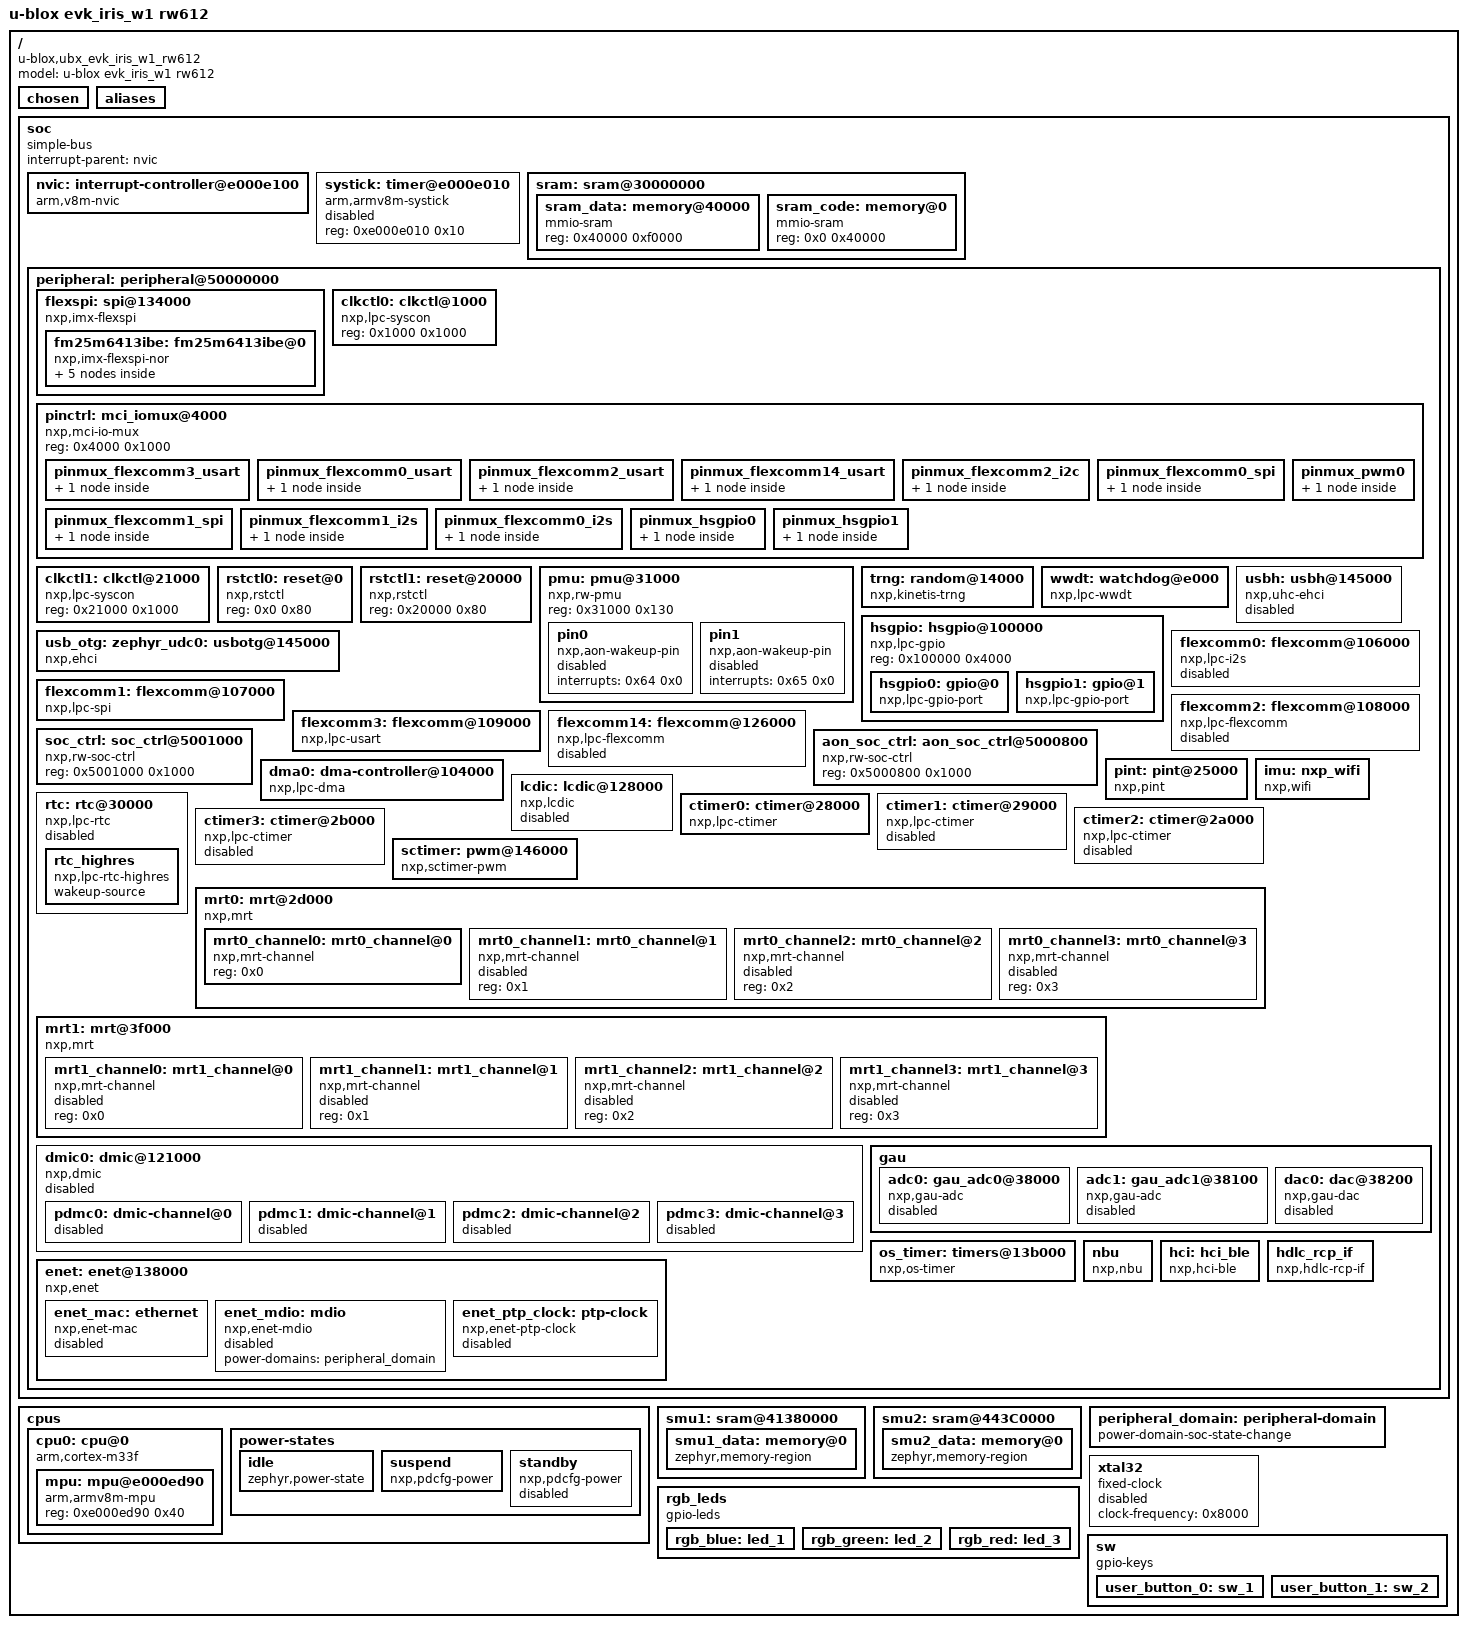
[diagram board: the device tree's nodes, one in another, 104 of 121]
/dts-v1/;

/* node '/' defined in zephyr/dts/common/skeleton.dtsi:9 */
/ {
	#address-cells = < 0x1 >;                    /* in zephyr/dts/common/skeleton.dtsi:10 */
	#size-cells = < 0x1 >;                       /* in zephyr/dts/common/skeleton.dtsi:11 */
	model = "u-blox evk_iris_w1 rw612";          /* in zephyr/boards/u-blox/ubx_evk_iris_w1/ubx_evk_iris_w1_common.dtsi:11 */
	compatible = "u-blox,ubx_evk_iris_w1_rw612"; /* in zephyr/boards/u-blox/ubx_evk_iris_w1/ubx_evk_iris_w1_common.dtsi:12 */

	/* node '/chosen' defined in zephyr/dts/common/skeleton.dtsi:13 */
	chosen {
		zephyr,entropy = &trng;                   /* in zephyr/dts/arm/nxp/nxp_rw6xx_common.dtsi:18 */
		zephyr,nbu = &nbu;                        /* in zephyr/dts/arm/nxp/nxp_rw6xx_common.dtsi:19 */
		zephyr,bt-hci = &hci;                     /* in zephyr/dts/arm/nxp/nxp_rw6xx_common.dtsi:20 */
		zephyr,hdlc-rcp-if = &hdlc_rcp_if;        /* in zephyr/dts/arm/nxp/nxp_rw6xx_common.dtsi:21 */
		zephyr,sram = &sram_data;                 /* in zephyr/boards/u-blox/ubx_evk_iris_w1/ubx_evk_iris_w1_common.dtsi:28 */
		zephyr,flash = &fm25m6413ibe;             /* in zephyr/boards/u-blox/ubx_evk_iris_w1/ubx_evk_iris_w1_common.dtsi:29 */
		zephyr,console = &flexcomm3;              /* in zephyr/boards/u-blox/ubx_evk_iris_w1/ubx_evk_iris_w1_common.dtsi:30 */
		zephyr,shell-uart = &flexcomm3;           /* in zephyr/boards/u-blox/ubx_evk_iris_w1/ubx_evk_iris_w1_common.dtsi:31 */
		zephyr,flash-controller = &fm25m6413ibe;  /* in zephyr/boards/u-blox/ubx_evk_iris_w1/ubx_evk_iris_w1_common.dtsi:32 */
		zephyr,code-partition = &slot0_partition; /* in zephyr/boards/u-blox/ubx_evk_iris_w1/ubx_evk_iris_w1_common.dtsi:33 */
		zephyr,uart-mcumgr = &flexcomm3;          /* in zephyr/boards/u-blox/ubx_evk_iris_w1/ubx_evk_iris_w1_common.dtsi:34 */
	};

	/* node '/aliases' defined in zephyr/dts/common/skeleton.dtsi:15 */
	aliases {
		led0 = &rgb_red;      /* in zephyr/boards/u-blox/ubx_evk_iris_w1/ubx_evk_iris_w1_common.dtsi:15 */
		led1 = &rgb_green;    /* in zephyr/boards/u-blox/ubx_evk_iris_w1/ubx_evk_iris_w1_common.dtsi:16 */
		led2 = &rgb_blue;     /* in zephyr/boards/u-blox/ubx_evk_iris_w1/ubx_evk_iris_w1_common.dtsi:17 */
		sw0 = &user_button_0; /* in zephyr/boards/u-blox/ubx_evk_iris_w1/ubx_evk_iris_w1_common.dtsi:18 */
		sw1 = &user_button_1; /* in zephyr/boards/u-blox/ubx_evk_iris_w1/ubx_evk_iris_w1_common.dtsi:19 */
		watchdog0 = &wwdt;    /* in zephyr/boards/u-blox/ubx_evk_iris_w1/ubx_evk_iris_w1_common.dtsi:20 */
		usart-0 = &flexcomm3; /* in zephyr/boards/u-blox/ubx_evk_iris_w1/ubx_evk_iris_w1_common.dtsi:21 */
		i2s-0 = &flexcomm0;   /* in zephyr/boards/u-blox/ubx_evk_iris_w1/ubx_evk_iris_w1_common.dtsi:22 */
		i2c-2 = &flexcomm2;   /* in zephyr/boards/u-blox/ubx_evk_iris_w1/ubx_evk_iris_w1_common.dtsi:23 */
		pwm-0 = &sctimer;     /* in zephyr/boards/u-blox/ubx_evk_iris_w1/ubx_evk_iris_w1_common.dtsi:24 */
	};

	/* node '/soc' defined in zephyr/dts/arm/armv8-m.dtsi:6 */
	soc {
		#address-cells = < 0x1 >;     /* in zephyr/dts/arm/armv8-m.dtsi:7 */
		#size-cells = < 0x1 >;        /* in zephyr/dts/arm/armv8-m.dtsi:8 */
		compatible = "simple-bus";    /* in zephyr/dts/arm/armv8-m.dtsi:9 */
		interrupt-parent = < &nvic >; /* in zephyr/dts/arm/armv8-m.dtsi:10 */
		ranges;                       /* in zephyr/dts/arm/armv8-m.dtsi:11 */

		/* node '/soc/interrupt-controller@e000e100' defined in zephyr/dts/arm/armv8-m.dtsi:13 */
		nvic: interrupt-controller@e000e100 {
			#address-cells = < 0x1 >;            /* in zephyr/dts/arm/armv8-m.dtsi:14 */
			compatible = "arm,v8m-nvic";         /* in zephyr/dts/arm/armv8-m.dtsi:15 */
			reg = < 0xe000e100 0xc00 >;          /* in zephyr/dts/arm/armv8-m.dtsi:16 */
			interrupt-controller;                /* in zephyr/dts/arm/armv8-m.dtsi:17 */
			#interrupt-cells = < 0x2 >;          /* in zephyr/dts/arm/armv8-m.dtsi:18 */
			arm,num-irq-priority-bits = < 0x3 >; /* in zephyr/dts/arm/nxp/nxp_rw6xx_common.dtsi:677 */
			phandle = < 0x1 >;                   /* in zephyr/dts/arm/armv8-m.dtsi:10 */
		};

		/* node '/soc/timer@e000e010' defined in zephyr/dts/arm/armv8-m.dtsi:21 */
		systick: timer@e000e010 {
			compatible = "arm,armv8m-systick"; /* in zephyr/dts/arm/armv8-m.dtsi:22 */
			reg = < 0xe000e010 0x10 >;         /* in zephyr/dts/arm/armv8-m.dtsi:23 */
			status = "disabled";               /* in zephyr/boards/u-blox/ubx_evk_iris_w1/ubx_evk_iris_w1_common.dtsi:181 */
		};

		/* node '/soc/sram@30000000' defined in zephyr/dts/arm/nxp/nxp_rw6xx.dtsi:13 */
		sram: sram@30000000 {
			ranges = < 0x20000000 0x30000000 0x130000 0x0 0x10000000 0x130000 >; /* in zephyr/dts/arm/nxp/nxp_rw6xx.dtsi:14 */
			#address-cells = < 0x1 >;                                            /* in zephyr/dts/arm/nxp/nxp_rw6xx_common.dtsi:103 */
			#size-cells = < 0x1 >;                                               /* in zephyr/dts/arm/nxp/nxp_rw6xx_common.dtsi:104 */

			/* node '/soc/sram@30000000/memory@40000' defined in zephyr/dts/arm/nxp/nxp_rw6xx_common.dtsi:111 */
			sram_data: memory@40000 {
				compatible = "mmio-sram";  /* in zephyr/dts/arm/nxp/nxp_rw6xx_common.dtsi:112 */
				reg = < 0x40000 0xf0000 >; /* in zephyr/dts/arm/nxp/nxp_rw6xx_common.dtsi:113 */
			};

			/* node '/soc/sram@30000000/memory@0' defined in zephyr/dts/arm/nxp/nxp_rw6xx_common.dtsi:116 */
			sram_code: memory@0 {
				compatible = "mmio-sram"; /* in zephyr/dts/arm/nxp/nxp_rw6xx_common.dtsi:117 */
				reg = < 0x0 0x40000 >;    /* in zephyr/dts/arm/nxp/nxp_rw6xx_common.dtsi:118 */
			};
		};

		/* node '/soc/peripheral@50000000' defined in zephyr/dts/arm/nxp/nxp_rw6xx.dtsi:18 */
		peripheral: peripheral@50000000 {
			ranges = < 0x0 0x50000000 0x10000000 >; /* in zephyr/dts/arm/nxp/nxp_rw6xx.dtsi:19 */
			#address-cells = < 0x1 >;               /* in zephyr/dts/arm/nxp/nxp_rw6xx_common.dtsi:147 */
			#size-cells = < 0x1 >;                  /* in zephyr/dts/arm/nxp/nxp_rw6xx_common.dtsi:148 */

			/* node '/soc/peripheral@50000000/spi@134000' defined in zephyr/dts/arm/nxp/nxp_rw6xx_common.dtsi:150 */
			flexspi: spi@134000 {
				reg = < 0x134000 0x1000 >,
				      < 0x18000000 0x8000000 >; /* in zephyr/dts/arm/nxp/nxp_rw6xx_common.dtsi:151 */
				compatible = "nxp,imx-flexspi"; /* in zephyr/dts/arm/nxp/nxp_rw6xx_common.dtsi:668 */
				interrupts = < 0x2a 0x0 >;      /* in zephyr/dts/arm/nxp/nxp_rw6xx_common.dtsi:670 */
				#address-cells = < 0x1 >;       /* in zephyr/dts/arm/nxp/nxp_rw6xx_common.dtsi:671 */
				#size-cells = < 0x0 >;          /* in zephyr/dts/arm/nxp/nxp_rw6xx_common.dtsi:672 */
				clocks = < &clkctl1 0xa00 >;    /* in zephyr/dts/arm/nxp/nxp_rw6xx_common.dtsi:673 */
				status = "okay";                /* in zephyr/boards/u-blox/ubx_evk_iris_w1/ubx_evk_iris_w1_common.dtsi:101 */
				ahb-bufferable;                 /* in zephyr/boards/u-blox/ubx_evk_iris_w1/ubx_evk_iris_w1_common.dtsi:102 */
				ahb-prefetch;                   /* in zephyr/boards/u-blox/ubx_evk_iris_w1/ubx_evk_iris_w1_common.dtsi:103 */
				ahb-cacheable;                  /* in zephyr/boards/u-blox/ubx_evk_iris_w1/ubx_evk_iris_w1_common.dtsi:104 */
				ahb-read-addr-opt;              /* in zephyr/boards/u-blox/ubx_evk_iris_w1/ubx_evk_iris_w1_common.dtsi:105 */
				ahb-boundary = "1024";          /* in zephyr/boards/u-blox/ubx_evk_iris_w1/ubx_evk_iris_w1_common.dtsi:106 */
				rx-clock-source = < 0x1 >;      /* in zephyr/boards/u-blox/ubx_evk_iris_w1/ubx_evk_iris_w1_common.dtsi:107 */
				rx-clock-source-b = < 0x1 >;    /* in zephyr/boards/u-blox/ubx_evk_iris_w1/ubx_evk_iris_w1_common.dtsi:108 */

				/* node '/soc/peripheral@50000000/spi@134000/fm25m6413ibe@0' defined in zephyr/boards/u-blox/ubx_evk_iris_w1/ubx_evk_iris_w1_common.dtsi:111 */
				fm25m6413ibe: fm25m6413ibe@0 {
					compatible = "nxp,imx-flexspi-nor"; /* in zephyr/boards/u-blox/ubx_evk_iris_w1/ubx_evk_iris_w1_common.dtsi:112 */
					reg = < 0x0 >;                      /* in zephyr/boards/u-blox/ubx_evk_iris_w1/ubx_evk_iris_w1_common.dtsi:113 */
					size = < 0x4000000 >;               /* in zephyr/boards/u-blox/ubx_evk_iris_w1/ubx_evk_iris_w1_common.dtsi:114 */
					status = "okay";                    /* in zephyr/boards/u-blox/ubx_evk_iris_w1/ubx_evk_iris_w1_common.dtsi:115 */
					erase-block-size = < 0x1000 >;      /* in zephyr/boards/u-blox/ubx_evk_iris_w1/ubx_evk_iris_w1_common.dtsi:116 */
					write-block-size = < 0x1 >;         /* in zephyr/boards/u-blox/ubx_evk_iris_w1/ubx_evk_iris_w1_common.dtsi:117 */
					spi-max-frequency = < 0x7ed6b40 >;  /* in zephyr/boards/u-blox/ubx_evk_iris_w1/ubx_evk_iris_w1_common.dtsi:118 */

					/* node '/soc/peripheral@50000000/spi@134000/fm25m6413ibe@0/partitions' defined in zephyr/boards/u-blox/ubx_evk_iris_w1/ubx_evk_iris_w1_common.dtsi:120 */
					partitions {
						compatible = "fixed-partitions"; /* in zephyr/boards/u-blox/ubx_evk_iris_w1/ubx_evk_iris_w1_common.dtsi:121 */
						#address-cells = < 0x1 >;        /* in zephyr/boards/u-blox/ubx_evk_iris_w1/ubx_evk_iris_w1_common.dtsi:122 */
						#size-cells = < 0x1 >;           /* in zephyr/boards/u-blox/ubx_evk_iris_w1/ubx_evk_iris_w1_common.dtsi:123 */

						/* node '/soc/peripheral@50000000/spi@134000/fm25m6413ibe@0/partitions/partition@0' defined in zephyr/boards/u-blox/ubx_evk_iris_w1/ubx_evk_iris_w1_common.dtsi:129 */
						boot_partition: partition@0 {
							label = "mcuboot";     /* in zephyr/boards/u-blox/ubx_evk_iris_w1/ubx_evk_iris_w1_common.dtsi:130 */
							reg = < 0x0 0x20000 >; /* in zephyr/boards/u-blox/ubx_evk_iris_w1/ubx_evk_iris_w1_common.dtsi:131 */
						};

						/* node '/soc/peripheral@50000000/spi@134000/fm25m6413ibe@0/partitions/partition@20000' defined in zephyr/boards/u-blox/ubx_evk_iris_w1/ubx_evk_iris_w1_common.dtsi:134 */
						slot0_partition: partition@20000 {
							label = "image-0";          /* in zephyr/boards/u-blox/ubx_evk_iris_w1/ubx_evk_iris_w1_common.dtsi:135 */
							reg = < 0x20000 0x300000 >; /* in zephyr/boards/u-blox/ubx_evk_iris_w1/ubx_evk_iris_w1_common.dtsi:136 */
						};

						/* node '/soc/peripheral@50000000/spi@134000/fm25m6413ibe@0/partitions/partition@320000' defined in zephyr/boards/u-blox/ubx_evk_iris_w1/ubx_evk_iris_w1_common.dtsi:139 */
						slot1_partition: partition@320000 {
							label = "image-1";           /* in zephyr/boards/u-blox/ubx_evk_iris_w1/ubx_evk_iris_w1_common.dtsi:140 */
							reg = < 0x320000 0x300000 >; /* in zephyr/boards/u-blox/ubx_evk_iris_w1/ubx_evk_iris_w1_common.dtsi:141 */
						};

						/* node '/soc/peripheral@50000000/spi@134000/fm25m6413ibe@0/partitions/partition@620000' defined in zephyr/boards/u-blox/ubx_evk_iris_w1/ubx_evk_iris_w1_common.dtsi:144 */
						storage_partition: partition@620000 {
							label = "storage";           /* in zephyr/boards/u-blox/ubx_evk_iris_w1/ubx_evk_iris_w1_common.dtsi:145 */
							reg = < 0x620000 0x1e0000 >; /* in zephyr/boards/u-blox/ubx_evk_iris_w1/ubx_evk_iris_w1_common.dtsi:146 */
						};
					};
				};
			};

			/* node '/soc/peripheral@50000000/clkctl@1000' defined in zephyr/dts/arm/nxp/nxp_rw6xx_common.dtsi:154 */
			clkctl0: clkctl@1000 {
				compatible = "nxp,lpc-syscon"; /* in zephyr/dts/arm/nxp/nxp_rw6xx_common.dtsi:156 */
				reg = < 0x1000 0x1000 >;       /* in zephyr/dts/arm/nxp/nxp_rw6xx_common.dtsi:157 */
				#clock-cells = < 0x1 >;        /* in zephyr/dts/arm/nxp/nxp_rw6xx_common.dtsi:158 */
			};

			/* node '/soc/peripheral@50000000/mci_iomux@4000' defined in zephyr/dts/arm/nxp/nxp_rw6xx_common.dtsi:161 */
			pinctrl: mci_iomux@4000 {
				compatible = "nxp,mci-io-mux"; /* in zephyr/dts/arm/nxp/nxp_rw6xx_common.dtsi:162 */
				reg = < 0x4000 0x1000 >;       /* in zephyr/dts/arm/nxp/nxp_rw6xx_common.dtsi:163 */
				status = "okay";               /* in zephyr/dts/arm/nxp/nxp_rw6xx_common.dtsi:164 */

				/* node '/soc/peripheral@50000000/mci_iomux@4000/pinmux_flexcomm3_usart' defined in zephyr/boards/u-blox/ubx_evk_iris_w1/ubx_evk_iris_w1_rw612-pinctrl.dtsi:11 */
				pinmux_flexcomm3_usart: pinmux_flexcomm3_usart {
					phandle = < 0xc >; /* in zephyr/boards/u-blox/ubx_evk_iris_w1/ubx_evk_iris_w1_common.dtsi:77 */

					/* node '/soc/peripheral@50000000/mci_iomux@4000/pinmux_flexcomm3_usart/group0' defined in zephyr/boards/u-blox/ubx_evk_iris_w1/ubx_evk_iris_w1_rw612-pinctrl.dtsi:12 */
					group0 {
						pinmux = < 0x49818 0x4981a >; /* in zephyr/boards/u-blox/ubx_evk_iris_w1/ubx_evk_iris_w1_rw612-pinctrl.dtsi:13 */
						slew-rate = "normal";         /* in zephyr/boards/u-blox/ubx_evk_iris_w1/ubx_evk_iris_w1_rw612-pinctrl.dtsi:14 */
					};
				};

				/* node '/soc/peripheral@50000000/mci_iomux@4000/pinmux_flexcomm0_usart' defined in zephyr/boards/u-blox/ubx_evk_iris_w1/ubx_evk_iris_w1_rw612-pinctrl.dtsi:19 */
				pinmux_flexcomm0_usart: pinmux_flexcomm0_usart {

					/* node '/soc/peripheral@50000000/mci_iomux@4000/pinmux_flexcomm0_usart/group0' defined in zephyr/boards/u-blox/ubx_evk_iris_w1/ubx_evk_iris_w1_rw612-pinctrl.dtsi:20 */
					group0 {
						pinmux = < 0x48002 0x48003 >; /* in zephyr/boards/u-blox/ubx_evk_iris_w1/ubx_evk_iris_w1_rw612-pinctrl.dtsi:21 */
						slew-rate = "normal";         /* in zephyr/boards/u-blox/ubx_evk_iris_w1/ubx_evk_iris_w1_rw612-pinctrl.dtsi:22 */
					};
				};

				/* node '/soc/peripheral@50000000/mci_iomux@4000/pinmux_flexcomm2_usart' defined in zephyr/boards/u-blox/ubx_evk_iris_w1/ubx_evk_iris_w1_rw612-pinctrl.dtsi:26 */
				pinmux_flexcomm2_usart: pinmux_flexcomm2_usart {

					/* node '/soc/peripheral@50000000/mci_iomux@4000/pinmux_flexcomm2_usart/group0' defined in zephyr/boards/u-blox/ubx_evk_iris_w1/ubx_evk_iris_w1_rw612-pinctrl.dtsi:27 */
					group0 {
						pinmux = < 0x4900d 0x4900e >; /* in zephyr/boards/u-blox/ubx_evk_iris_w1/ubx_evk_iris_w1_rw612-pinctrl.dtsi:28 */
						slew-rate = "normal";         /* in zephyr/boards/u-blox/ubx_evk_iris_w1/ubx_evk_iris_w1_rw612-pinctrl.dtsi:29 */
					};
				};

				/* node '/soc/peripheral@50000000/mci_iomux@4000/pinmux_flexcomm14_usart' defined in zephyr/boards/u-blox/ubx_evk_iris_w1/ubx_evk_iris_w1_rw612-pinctrl.dtsi:33 */
				pinmux_flexcomm14_usart: pinmux_flexcomm14_usart {

					/* node '/soc/peripheral@50000000/mci_iomux@4000/pinmux_flexcomm14_usart/group0' defined in zephyr/boards/u-blox/ubx_evk_iris_w1/ubx_evk_iris_w1_rw612-pinctrl.dtsi:34 */
					group0 {
						pinmux = < 0x4b038 0x4b039 >; /* in zephyr/boards/u-blox/ubx_evk_iris_w1/ubx_evk_iris_w1_rw612-pinctrl.dtsi:35 */
						slew-rate = "normal";         /* in zephyr/boards/u-blox/ubx_evk_iris_w1/ubx_evk_iris_w1_rw612-pinctrl.dtsi:36 */
					};
				};

				/* node '/soc/peripheral@50000000/mci_iomux@4000/pinmux_flexcomm2_i2c' defined in zephyr/boards/u-blox/ubx_evk_iris_w1/ubx_evk_iris_w1_rw612-pinctrl.dtsi:41 */
				pinmux_flexcomm2_i2c: pinmux_flexcomm2_i2c {

					/* node '/soc/peripheral@50000000/mci_iomux@4000/pinmux_flexcomm2_i2c/group0' defined in zephyr/boards/u-blox/ubx_evk_iris_w1/ubx_evk_iris_w1_rw612-pinctrl.dtsi:42 */
					group0 {
						pinmux = < 0x21010 0x21011 >; /* in zephyr/boards/u-blox/ubx_evk_iris_w1/ubx_evk_iris_w1_rw612-pinctrl.dtsi:43 */
						slew-rate = "normal";         /* in zephyr/boards/u-blox/ubx_evk_iris_w1/ubx_evk_iris_w1_rw612-pinctrl.dtsi:44 */
						bias-pull-up;                 /* in zephyr/boards/u-blox/ubx_evk_iris_w1/ubx_evk_iris_w1_rw612-pinctrl.dtsi:45 */
					};
				};

				/* node '/soc/peripheral@50000000/mci_iomux@4000/pinmux_flexcomm0_spi' defined in zephyr/boards/u-blox/ubx_evk_iris_w1/ubx_evk_iris_w1_rw612-pinctrl.dtsi:50 */
				pinmux_flexcomm0_spi: pinmux_flexcomm0_spi {

					/* node '/soc/peripheral@50000000/mci_iomux@4000/pinmux_flexcomm0_spi/group0' defined in zephyr/boards/u-blox/ubx_evk_iris_w1/ubx_evk_iris_w1_rw612-pinctrl.dtsi:51 */
					group0 {
						pinmux = < 0x18000 0x18002 0x18003 0x18004 >; /* in zephyr/boards/u-blox/ubx_evk_iris_w1/ubx_evk_iris_w1_rw612-pinctrl.dtsi:52 */
						slew-rate = "ultra";                          /* in zephyr/boards/u-blox/ubx_evk_iris_w1/ubx_evk_iris_w1_rw612-pinctrl.dtsi:53 */
					};
				};

				/* node '/soc/peripheral@50000000/mci_iomux@4000/pinmux_flexcomm1_spi' defined in zephyr/boards/u-blox/ubx_evk_iris_w1/ubx_evk_iris_w1_rw612-pinctrl.dtsi:58 */
				pinmux_flexcomm1_spi: pinmux_flexcomm1_spi {
					phandle = < 0xb >; /* in zephyr/boards/u-blox/ubx_evk_iris_w1/ubx_evk_iris_w1_common.dtsi:211 */

					/* node '/soc/peripheral@50000000/mci_iomux@4000/pinmux_flexcomm1_spi/group0' defined in zephyr/boards/u-blox/ubx_evk_iris_w1/ubx_evk_iris_w1_rw612-pinctrl.dtsi:59 */
					group0 {
						pinmux = < 0x18806 0x18807 0x18808 0x18809 >; /* in zephyr/boards/u-blox/ubx_evk_iris_w1/ubx_evk_iris_w1_rw612-pinctrl.dtsi:60 */
						slew-rate = "ultra";                          /* in zephyr/boards/u-blox/ubx_evk_iris_w1/ubx_evk_iris_w1_rw612-pinctrl.dtsi:61 */
					};
				};

				/* node '/soc/peripheral@50000000/mci_iomux@4000/pinmux_flexcomm1_i2s' defined in zephyr/boards/u-blox/ubx_evk_iris_w1/ubx_evk_iris_w1_rw612-pinctrl.dtsi:66 */
				pinmux_flexcomm1_i2s: pinmux_flexcomm1_i2s {

					/* node '/soc/peripheral@50000000/mci_iomux@4000/pinmux_flexcomm1_i2s/group0' defined in zephyr/boards/u-blox/ubx_evk_iris_w1/ubx_evk_iris_w1_rw612-pinctrl.dtsi:67 */
					group0 {
						pinmux = < 0x10807 0x10808 0x10809 >; /* in zephyr/boards/u-blox/ubx_evk_iris_w1/ubx_evk_iris_w1_rw612-pinctrl.dtsi:68 */
						slew-rate = "normal";                 /* in zephyr/boards/u-blox/ubx_evk_iris_w1/ubx_evk_iris_w1_rw612-pinctrl.dtsi:69 */
					};
				};

				/* node '/soc/peripheral@50000000/mci_iomux@4000/pinmux_flexcomm0_i2s' defined in zephyr/boards/u-blox/ubx_evk_iris_w1/ubx_evk_iris_w1_rw612-pinctrl.dtsi:73 */
				pinmux_flexcomm0_i2s: pinmux_flexcomm0_i2s {
					phandle = < 0xa >; /* in zephyr/boards/u-blox/ubx_evk_iris_w1/ubx_evk_iris_w1_common.dtsi:84 */

					/* node '/soc/peripheral@50000000/mci_iomux@4000/pinmux_flexcomm0_i2s/group0' defined in zephyr/boards/u-blox/ubx_evk_iris_w1/ubx_evk_iris_w1_rw612-pinctrl.dtsi:74 */
					group0 {
						pinmux = < 0x10002 0x10003 0x10004 >; /* in zephyr/boards/u-blox/ubx_evk_iris_w1/ubx_evk_iris_w1_rw612-pinctrl.dtsi:75 */
						slew-rate = "normal";                 /* in zephyr/boards/u-blox/ubx_evk_iris_w1/ubx_evk_iris_w1_rw612-pinctrl.dtsi:76 */
					};
				};

				/* node '/soc/peripheral@50000000/mci_iomux@4000/pinmux_pwm0' defined in zephyr/boards/u-blox/ubx_evk_iris_w1/ubx_evk_iris_w1_rw612-pinctrl.dtsi:80 */
				pinmux_pwm0: pinmux_pwm0 {
					phandle = < 0xd >; /* in zephyr/boards/u-blox/ubx_evk_iris_w1/ubx_evk_iris_w1_common.dtsi:186 */

					/* node '/soc/peripheral@50000000/mci_iomux@4000/pinmux_pwm0/group0' defined in zephyr/boards/u-blox/ubx_evk_iris_w1/ubx_evk_iris_w1_rw612-pinctrl.dtsi:81 */
					group0 {
						pinmux = < 0x283 >;   /* in zephyr/boards/u-blox/ubx_evk_iris_w1/ubx_evk_iris_w1_rw612-pinctrl.dtsi:82 */
						slew-rate = "normal"; /* in zephyr/boards/u-blox/ubx_evk_iris_w1/ubx_evk_iris_w1_rw612-pinctrl.dtsi:83 */
					};
				};

				/* node '/soc/peripheral@50000000/mci_iomux@4000/pinmux_hsgpio0' defined in zephyr/boards/u-blox/ubx_evk_iris_w1/ubx_evk_iris_w1_rw612-pinctrl.dtsi:87 */
				pinmux_hsgpio0: pinmux_hsgpio0 {
					phandle = < 0x4 >; /* in zephyr/boards/u-blox/ubx_evk_iris_w1/ubx_evk_iris_w1_common.dtsi:90 */

					/* node '/soc/peripheral@50000000/mci_iomux@4000/pinmux_hsgpio0/group0' defined in zephyr/boards/u-blox/ubx_evk_iris_w1/ubx_evk_iris_w1_rw612-pinctrl.dtsi:88 */
					group0 {
						pinmux = < 0x30b 0x30c 0x312 0x315 >; /* in zephyr/boards/u-blox/ubx_evk_iris_w1/ubx_evk_iris_w1_rw612-pinctrl.dtsi:89 */
						slew-rate = "normal";                 /* in zephyr/boards/u-blox/ubx_evk_iris_w1/ubx_evk_iris_w1_rw612-pinctrl.dtsi:93 */
					};
				};

				/* node '/soc/peripheral@50000000/mci_iomux@4000/pinmux_hsgpio1' defined in zephyr/boards/u-blox/ubx_evk_iris_w1/ubx_evk_iris_w1_rw612-pinctrl.dtsi:97 */
				pinmux_hsgpio1: pinmux_hsgpio1 {
					phandle = < 0x5 >; /* in zephyr/boards/u-blox/ubx_evk_iris_w1/ubx_evk_iris_w1_common.dtsi:96 */

					/* node '/soc/peripheral@50000000/mci_iomux@4000/pinmux_hsgpio1/group0' defined in zephyr/boards/u-blox/ubx_evk_iris_w1/ubx_evk_iris_w1_rw612-pinctrl.dtsi:98 */
					group0 {
						pinmux = < 0x32c 0x337 >; /* in zephyr/boards/u-blox/ubx_evk_iris_w1/ubx_evk_iris_w1_rw612-pinctrl.dtsi:99 */
						slew-rate = "normal";     /* in zephyr/boards/u-blox/ubx_evk_iris_w1/ubx_evk_iris_w1_rw612-pinctrl.dtsi:101 */
					};
				};
			};

			/* node '/soc/peripheral@50000000/clkctl@21000' defined in zephyr/dts/arm/nxp/nxp_rw6xx_common.dtsi:167 */
			clkctl1: clkctl@21000 {
				compatible = "nxp,lpc-syscon"; /* in zephyr/dts/arm/nxp/nxp_rw6xx_common.dtsi:169 */
				reg = < 0x21000 0x1000 >;      /* in zephyr/dts/arm/nxp/nxp_rw6xx_common.dtsi:170 */
				#clock-cells = < 0x1 >;        /* in zephyr/dts/arm/nxp/nxp_rw6xx_common.dtsi:171 */
				phandle = < 0x2 >;             /* in zephyr/dts/arm/nxp/nxp_rw6xx_common.dtsi:673 */
			};

			/* node '/soc/peripheral@50000000/reset@0' defined in zephyr/dts/arm/nxp/nxp_rw6xx_common.dtsi:174 */
			rstctl0: reset@0 {
				compatible = "nxp,rstctl"; /* in zephyr/dts/arm/nxp/nxp_rw6xx_common.dtsi:175 */
				reg = < 0x0 0x80 >;        /* in zephyr/dts/arm/nxp/nxp_rw6xx_common.dtsi:176 */
				#reset-cells = < 0x1 >;    /* in zephyr/dts/arm/nxp/nxp_rw6xx_common.dtsi:177 */
				phandle = < 0xe >;         /* in zephyr/dts/arm/nxp/nxp_rw6xx_common.dtsi:511 */
			};

			/* node '/soc/peripheral@50000000/reset@20000' defined in zephyr/dts/arm/nxp/nxp_rw6xx_common.dtsi:180 */
			rstctl1: reset@20000 {
				compatible = "nxp,rstctl"; /* in zephyr/dts/arm/nxp/nxp_rw6xx_common.dtsi:181 */
				reg = < 0x20000 0x80 >;    /* in zephyr/dts/arm/nxp/nxp_rw6xx_common.dtsi:182 */
				#reset-cells = < 0x1 >;    /* in zephyr/dts/arm/nxp/nxp_rw6xx_common.dtsi:183 */
				phandle = < 0x6 >;         /* in zephyr/dts/arm/nxp/nxp_rw6xx_common.dtsi:270 */
			};

			/* node '/soc/peripheral@50000000/pmu@31000' defined in zephyr/dts/arm/nxp/nxp_rw6xx_common.dtsi:186 */
			pmu: pmu@31000 {
				reg = < 0x31000 0x130 >;   /* in zephyr/dts/arm/nxp/nxp_rw6xx_common.dtsi:187 */
				compatible = "nxp,rw-pmu"; /* in zephyr/dts/arm/nxp/nxp_rw6xx_common.dtsi:188 */

				/* node '/soc/peripheral@50000000/pmu@31000/pin0' defined in zephyr/dts/arm/nxp/nxp_rw6xx_common.dtsi:190 */
				pin0: pin0 {
					compatible = "nxp,aon-wakeup-pin"; /* in zephyr/dts/arm/nxp/nxp_rw6xx_common.dtsi:191 */
					interrupts = < 0x64 0x0 >;         /* in zephyr/dts/arm/nxp/nxp_rw6xx_common.dtsi:192 */
					status = "disabled";               /* in zephyr/dts/arm/nxp/nxp_rw6xx_common.dtsi:193 */
				};

				/* node '/soc/peripheral@50000000/pmu@31000/pin1' defined in zephyr/dts/arm/nxp/nxp_rw6xx_common.dtsi:196 */
				pin1: pin1 {
					compatible = "nxp,aon-wakeup-pin"; /* in zephyr/dts/arm/nxp/nxp_rw6xx_common.dtsi:197 */
					interrupts = < 0x65 0x0 >;         /* in zephyr/dts/arm/nxp/nxp_rw6xx_common.dtsi:198 */
					status = "disabled";               /* in zephyr/dts/arm/nxp/nxp_rw6xx_common.dtsi:199 */
				};
			};

			/* node '/soc/peripheral@50000000/random@14000' defined in zephyr/dts/arm/nxp/nxp_rw6xx_common.dtsi:203 */
			trng: random@14000 {
				compatible = "nxp,kinetis-trng";        /* in zephyr/dts/arm/nxp/nxp_rw6xx_common.dtsi:204 */
				reg = < 0x14000 0x1000 >;               /* in zephyr/dts/arm/nxp/nxp_rw6xx_common.dtsi:205 */
				status = "okay";                        /* in zephyr/dts/arm/nxp/nxp_rw6xx_common.dtsi:206 */
				interrupts = < 0x7b 0x0 >;              /* in zephyr/dts/arm/nxp/nxp_rw6xx_common.dtsi:207 */
				power-domains = < &peripheral_domain >; /* in zephyr/dts/arm/nxp/nxp_rw6xx_common.dtsi:208 */
			};

			/* node '/soc/peripheral@50000000/watchdog@e000' defined in zephyr/dts/arm/nxp/nxp_rw6xx_common.dtsi:211 */
			wwdt: watchdog@e000 {
				compatible = "nxp,lpc-wwdt";            /* in zephyr/dts/arm/nxp/nxp_rw6xx_common.dtsi:212 */
				reg = < 0xe000 0x1000 >;                /* in zephyr/dts/arm/nxp/nxp_rw6xx_common.dtsi:213 */
				interrupts = < 0x0 0x0 >;               /* in zephyr/dts/arm/nxp/nxp_rw6xx_common.dtsi:214 */
				power-domains = < &peripheral_domain >; /* in zephyr/dts/arm/nxp/nxp_rw6xx_common.dtsi:216 */
				clk-divider = < 0x1 >;                  /* in zephyr/dts/arm/nxp/nxp_rw6xx_common.dtsi:217 */
				status = "okay";                        /* in zephyr/boards/u-blox/ubx_evk_iris_w1/ubx_evk_iris_w1_common.dtsi:158 */
			};

			/* node '/soc/peripheral@50000000/hsgpio@100000' defined in zephyr/dts/arm/nxp/nxp_rw6xx_common.dtsi:220 */
			hsgpio: hsgpio@100000 {
				compatible = "nxp,lpc-gpio"; /* in zephyr/dts/arm/nxp/nxp_rw6xx_common.dtsi:221 */
				reg = < 0x100000 0x4000 >;   /* in zephyr/dts/arm/nxp/nxp_rw6xx_common.dtsi:222 */
				#address-cells = < 0x1 >;    /* in zephyr/dts/arm/nxp/nxp_rw6xx_common.dtsi:223 */
				#size-cells = < 0x0 >;       /* in zephyr/dts/arm/nxp/nxp_rw6xx_common.dtsi:224 */

				/* node '/soc/peripheral@50000000/hsgpio@100000/gpio@0' defined in zephyr/dts/arm/nxp/nxp_rw6xx_common.dtsi:226 */
				hsgpio0: gpio@0 {
					compatible = "nxp,lpc-gpio-port";       /* in zephyr/dts/arm/nxp/nxp_rw6xx_common.dtsi:227 */
					gpio-controller;                        /* in zephyr/dts/arm/nxp/nxp_rw6xx_common.dtsi:228 */
					#gpio-cells = < 0x2 >;                  /* in zephyr/dts/arm/nxp/nxp_rw6xx_common.dtsi:229 */
					reg = < 0x0 >;                          /* in zephyr/dts/arm/nxp/nxp_rw6xx_common.dtsi:230 */
					int-source = "pint";                    /* in zephyr/dts/arm/nxp/nxp_rw6xx_common.dtsi:231 */
					power-domains = < &peripheral_domain >; /* in zephyr/dts/arm/nxp/nxp_rw6xx_common.dtsi:232 */
					status = "okay";                        /* in zephyr/boards/u-blox/ubx_evk_iris_w1/ubx_evk_iris_w1_common.dtsi:89 */
					pinctrl-0 = < &pinmux_hsgpio0 >;        /* in zephyr/boards/u-blox/ubx_evk_iris_w1/ubx_evk_iris_w1_common.dtsi:90 */
					pinctrl-names = "default";              /* in zephyr/boards/u-blox/ubx_evk_iris_w1/ubx_evk_iris_w1_common.dtsi:91 */
				};

				/* node '/soc/peripheral@50000000/hsgpio@100000/gpio@1' defined in zephyr/dts/arm/nxp/nxp_rw6xx_common.dtsi:235 */
				hsgpio1: gpio@1 {
					compatible = "nxp,lpc-gpio-port";       /* in zephyr/dts/arm/nxp/nxp_rw6xx_common.dtsi:236 */
					gpio-controller;                        /* in zephyr/dts/arm/nxp/nxp_rw6xx_common.dtsi:237 */
					#gpio-cells = < 0x2 >;                  /* in zephyr/dts/arm/nxp/nxp_rw6xx_common.dtsi:238 */
					reg = < 0x1 >;                          /* in zephyr/dts/arm/nxp/nxp_rw6xx_common.dtsi:239 */
					int-source = "pint";                    /* in zephyr/dts/arm/nxp/nxp_rw6xx_common.dtsi:240 */
					power-domains = < &peripheral_domain >; /* in zephyr/dts/arm/nxp/nxp_rw6xx_common.dtsi:241 */
					status = "okay";                        /* in zephyr/boards/u-blox/ubx_evk_iris_w1/ubx_evk_iris_w1_common.dtsi:95 */
					pinctrl-0 = < &pinmux_hsgpio1 >;        /* in zephyr/boards/u-blox/ubx_evk_iris_w1/ubx_evk_iris_w1_common.dtsi:96 */
					pinctrl-names = "default";              /* in zephyr/boards/u-blox/ubx_evk_iris_w1/ubx_evk_iris_w1_common.dtsi:97 */
					phandle = < 0x13 >;                     /* in zephyr/boards/u-blox/ubx_evk_iris_w1/ubx_evk_iris_w1_common.dtsi:41 */
				};
			};

			/* node '/soc/peripheral@50000000/usbotg@145000' defined in zephyr/dts/arm/nxp/nxp_rw6xx_common.dtsi:245 */
			usb_otg: zephyr_udc0: usbotg@145000 {
				compatible = "nxp,ehci";                /* in zephyr/dts/arm/nxp/nxp_rw6xx_common.dtsi:246 */
				reg = < 0x145000 0x200 >;               /* in zephyr/dts/arm/nxp/nxp_rw6xx_common.dtsi:247 */
				interrupts = < 0x32 0x1 >;              /* in zephyr/dts/arm/nxp/nxp_rw6xx_common.dtsi:248 */
				interrupt-names = "usb_otg";            /* in zephyr/dts/arm/nxp/nxp_rw6xx_common.dtsi:249 */
				num-bidir-endpoints = < 0x8 >;          /* in zephyr/dts/arm/nxp/nxp_rw6xx_common.dtsi:250 */
				power-domains = < &peripheral_domain >; /* in zephyr/dts/arm/nxp/nxp_rw6xx_common.dtsi:251 */
				status = "okay";                        /* in zephyr/boards/u-blox/ubx_evk_iris_w1/ubx_evk_iris_w1_common.dtsi:206 */
			};

			/* node '/soc/peripheral@50000000/usbh@145000' defined in zephyr/dts/arm/nxp/nxp_rw6xx_common.dtsi:255 */
			usbh: usbh@145000 {
				compatible = "nxp,uhc-ehci";            /* in zephyr/dts/arm/nxp/nxp_rw6xx_common.dtsi:256 */
				reg = < 0x145000 0x200 >;               /* in zephyr/dts/arm/nxp/nxp_rw6xx_common.dtsi:257 */
				interrupts = < 0x32 0x1 >;              /* in zephyr/dts/arm/nxp/nxp_rw6xx_common.dtsi:258 */
				interrupt-names = "usb_otg";            /* in zephyr/dts/arm/nxp/nxp_rw6xx_common.dtsi:259 */
				power-domains = < &peripheral_domain >; /* in zephyr/dts/arm/nxp/nxp_rw6xx_common.dtsi:260 */
				status = "disabled";                    /* in zephyr/dts/arm/nxp/nxp_rw6xx_common.dtsi:261 */
			};

			/* node '/soc/peripheral@50000000/flexcomm@106000' defined in zephyr/dts/arm/nxp/nxp_rw6xx_common.dtsi:264 */
			flexcomm0: flexcomm@106000 {
				reg = < 0x106000 0x1000 >;                             /* in zephyr/dts/arm/nxp/nxp_rw6xx_common.dtsi:266 */
				interrupts = < 0xe 0x0 >;                              /* in zephyr/dts/arm/nxp/nxp_rw6xx_common.dtsi:267 */
				clocks = < &clkctl1 0x100 &clkctl1 0x180 >;            /* in zephyr/dts/arm/nxp/nxp_rw6xx_common.dtsi:268 */
				clock-names = "default",
				              "sleep";                                 /* in zephyr/dts/arm/nxp/nxp_rw6xx_common.dtsi:269 */
				resets = < &rstctl1 0x8 >;                             /* in zephyr/dts/arm/nxp/nxp_rw6xx_common.dtsi:270 */
				dmas = < &dma0 0x0 >,
				       < &dma0 0x1 >;                                  /* in zephyr/dts/arm/nxp/nxp_rw6xx_common.dtsi:271 */
				dma-names = "rx",
				            "tx";                                      /* in zephyr/dts/arm/nxp/nxp_rw6xx_common.dtsi:272 */
				zephyr,disabling-power-states = < &suspend &standby >; /* in zephyr/dts/arm/nxp/nxp_rw6xx_common.dtsi:273 */
				low-power-states = < &suspend >;                       /* in zephyr/dts/arm/nxp/nxp_rw6xx_common.dtsi:274 */
				power-domains = < &peripheral_domain >;                /* in zephyr/dts/arm/nxp/nxp_rw6xx_common.dtsi:275 */
				compatible = "nxp,lpc-i2s";                            /* in zephyr/boards/u-blox/ubx_evk_iris_w1/ubx_evk_iris_w1_common.dtsi:82 */
				status = "disabled";                                   /* in zephyr/boards/u-blox/ubx_evk_iris_w1/ubx_evk_iris_w1_common.dtsi:83 */
				pinctrl-0 = < &pinmux_flexcomm0_i2s >;                 /* in zephyr/boards/u-blox/ubx_evk_iris_w1/ubx_evk_iris_w1_common.dtsi:84 */
				pinctrl-names = "default";                             /* in zephyr/boards/u-blox/ubx_evk_iris_w1/ubx_evk_iris_w1_common.dtsi:85 */
			};

			/* node '/soc/peripheral@50000000/flexcomm@107000' defined in zephyr/dts/arm/nxp/nxp_rw6xx_common.dtsi:279 */
			flexcomm1: flexcomm@107000 {
				reg = < 0x107000 0x1000 >;                             /* in zephyr/dts/arm/nxp/nxp_rw6xx_common.dtsi:281 */
				interrupts = < 0xf 0x0 >;                              /* in zephyr/dts/arm/nxp/nxp_rw6xx_common.dtsi:282 */
				clocks = < &clkctl1 0x101 &clkctl1 0x181 >;            /* in zephyr/dts/arm/nxp/nxp_rw6xx_common.dtsi:283 */
				clock-names = "default",
				              "sleep";                                 /* in zephyr/dts/arm/nxp/nxp_rw6xx_common.dtsi:284 */
				resets = < &rstctl1 0x9 >;                             /* in zephyr/dts/arm/nxp/nxp_rw6xx_common.dtsi:285 */
				dmas = < &dma0 0x2 >,
				       < &dma0 0x3 >;                                  /* in zephyr/dts/arm/nxp/nxp_rw6xx_common.dtsi:286 */
				dma-names = "rx",
				            "tx";                                      /* in zephyr/dts/arm/nxp/nxp_rw6xx_common.dtsi:287 */
				zephyr,disabling-power-states = < &suspend &standby >; /* in zephyr/dts/arm/nxp/nxp_rw6xx_common.dtsi:288 */
				low-power-states = < &suspend >;                       /* in zephyr/dts/arm/nxp/nxp_rw6xx_common.dtsi:289 */
				power-domains = < &peripheral_domain >;                /* in zephyr/dts/arm/nxp/nxp_rw6xx_common.dtsi:290 */
				compatible = "nxp,lpc-spi";                            /* in zephyr/boards/u-blox/ubx_evk_iris_w1/ubx_evk_iris_w1_common.dtsi:210 */
				pinctrl-0 = < &pinmux_flexcomm1_spi >;                 /* in zephyr/boards/u-blox/ubx_evk_iris_w1/ubx_evk_iris_w1_common.dtsi:211 */
				pinctrl-names = "default";                             /* in zephyr/boards/u-blox/ubx_evk_iris_w1/ubx_evk_iris_w1_common.dtsi:212 */
				status = "okay";                                       /* in zephyr/boards/u-blox/ubx_evk_iris_w1/ubx_evk_iris_w1_common.dtsi:213 */
				#address-cells = < 0x1 >;                              /* in zephyr/boards/u-blox/ubx_evk_iris_w1/ubx_evk_iris_w1_common.dtsi:214 */
				#size-cells = < 0x0 >;                                 /* in zephyr/boards/u-blox/ubx_evk_iris_w1/ubx_evk_iris_w1_common.dtsi:215 */
			};

			/* node '/soc/peripheral@50000000/flexcomm@108000' defined in zephyr/dts/arm/nxp/nxp_rw6xx_common.dtsi:294 */
			flexcomm2: flexcomm@108000 {
				compatible = "nxp,lpc-flexcomm";                       /* in zephyr/dts/arm/nxp/nxp_rw6xx_common.dtsi:295 */
				reg = < 0x108000 0x1000 >;                             /* in zephyr/dts/arm/nxp/nxp_rw6xx_common.dtsi:296 */
				interrupts = < 0x10 0x0 >;                             /* in zephyr/dts/arm/nxp/nxp_rw6xx_common.dtsi:297 */
				clocks = < &clkctl1 0x102 &clkctl1 0x182 >;            /* in zephyr/dts/arm/nxp/nxp_rw6xx_common.dtsi:298 */
				clock-names = "default",
				              "sleep";                                 /* in zephyr/dts/arm/nxp/nxp_rw6xx_common.dtsi:299 */
				resets = < &rstctl1 0xa >;                             /* in zephyr/dts/arm/nxp/nxp_rw6xx_common.dtsi:300 */
				dmas = < &dma0 0x4 >,
				       < &dma0 0x5 >;                                  /* in zephyr/dts/arm/nxp/nxp_rw6xx_common.dtsi:301 */
				dma-names = "rx",
				            "tx";                                      /* in zephyr/dts/arm/nxp/nxp_rw6xx_common.dtsi:302 */
				zephyr,disabling-power-states = < &suspend &standby >; /* in zephyr/dts/arm/nxp/nxp_rw6xx_common.dtsi:303 */
				low-power-states = < &suspend >;                       /* in zephyr/dts/arm/nxp/nxp_rw6xx_common.dtsi:304 */
				power-domains = < &peripheral_domain >;                /* in zephyr/dts/arm/nxp/nxp_rw6xx_common.dtsi:305 */
				status = "disabled";                                   /* in zephyr/dts/arm/nxp/nxp_rw6xx_common.dtsi:306 */
			};

			/* node '/soc/peripheral@50000000/flexcomm@109000' defined in zephyr/dts/arm/nxp/nxp_rw6xx_common.dtsi:309 */
			flexcomm3: flexcomm@109000 {
				reg = < 0x109000 0x1000 >;                             /* in zephyr/dts/arm/nxp/nxp_rw6xx_common.dtsi:311 */
				interrupts = < 0x11 0x0 >;                             /* in zephyr/dts/arm/nxp/nxp_rw6xx_common.dtsi:312 */
				clocks = < &clkctl1 0x103 &clkctl1 0x183 >;            /* in zephyr/dts/arm/nxp/nxp_rw6xx_common.dtsi:313 */
				clock-names = "default",
				              "sleep";                                 /* in zephyr/dts/arm/nxp/nxp_rw6xx_common.dtsi:314 */
				resets = < &rstctl1 0xb >;                             /* in zephyr/dts/arm/nxp/nxp_rw6xx_common.dtsi:315 */
				dmas = < &dma0 0x6 >,
				       < &dma0 0x7 >;                                  /* in zephyr/dts/arm/nxp/nxp_rw6xx_common.dtsi:316 */
				dma-names = "rx",
				            "tx";                                      /* in zephyr/dts/arm/nxp/nxp_rw6xx_common.dtsi:317 */
				zephyr,disabling-power-states = < &suspend &standby >; /* in zephyr/dts/arm/nxp/nxp_rw6xx_common.dtsi:318 */
				low-power-states = < &suspend >;                       /* in zephyr/dts/arm/nxp/nxp_rw6xx_common.dtsi:319 */
				power-domains = < &peripheral_domain >;                /* in zephyr/dts/arm/nxp/nxp_rw6xx_common.dtsi:320 */
				compatible = "nxp,lpc-usart";                          /* in zephyr/boards/u-blox/ubx_evk_iris_w1/ubx_evk_iris_w1_common.dtsi:74 */
				status = "okay";                                       /* in zephyr/boards/u-blox/ubx_evk_iris_w1/ubx_evk_iris_w1_common.dtsi:75 */
				current-speed = < 0x1c200 >;                           /* in zephyr/boards/u-blox/ubx_evk_iris_w1/ubx_evk_iris_w1_common.dtsi:76 */
				pinctrl-0 = < &pinmux_flexcomm3_usart >;               /* in zephyr/boards/u-blox/ubx_evk_iris_w1/ubx_evk_iris_w1_common.dtsi:77 */
				pinctrl-names = "default";                             /* in zephyr/boards/u-blox/ubx_evk_iris_w1/ubx_evk_iris_w1_common.dtsi:78 */
			};

			/* node '/soc/peripheral@50000000/flexcomm@126000' defined in zephyr/dts/arm/nxp/nxp_rw6xx_common.dtsi:324 */
			flexcomm14: flexcomm@126000 {
				compatible = "nxp,lpc-flexcomm";                       /* in zephyr/dts/arm/nxp/nxp_rw6xx_common.dtsi:325 */
				reg = < 0x126000 0x2000 >;                             /* in zephyr/dts/arm/nxp/nxp_rw6xx_common.dtsi:326 */
				interrupts = < 0x14 0x0 >;                             /* in zephyr/dts/arm/nxp/nxp_rw6xx_common.dtsi:327 */
				clocks = < &clkctl1 0x10e >;                           /* in zephyr/dts/arm/nxp/nxp_rw6xx_common.dtsi:328 */
				resets = < &rstctl1 0x16 >;                            /* in zephyr/dts/arm/nxp/nxp_rw6xx_common.dtsi:329 */
				dmas = < &dma0 0x1a >,
				       < &dma0 0x1b >;                                 /* in zephyr/dts/arm/nxp/nxp_rw6xx_common.dtsi:330 */
				dma-names = "rx",
				            "tx";                                      /* in zephyr/dts/arm/nxp/nxp_rw6xx_common.dtsi:331 */
				zephyr,disabling-power-states = < &suspend &standby >; /* in zephyr/dts/arm/nxp/nxp_rw6xx_common.dtsi:332 */
				power-domains = < &peripheral_domain >;                /* in zephyr/dts/arm/nxp/nxp_rw6xx_common.dtsi:333 */
				status = "disabled";                                   /* in zephyr/dts/arm/nxp/nxp_rw6xx_common.dtsi:334 */
			};

			/* node '/soc/peripheral@50000000/aon_soc_ctrl@5000800' defined in zephyr/dts/arm/nxp/nxp_rw6xx_common.dtsi:337 */
			aon_soc_ctrl: aon_soc_ctrl@5000800 {
				compatible = "nxp,rw-soc-ctrl"; /* in zephyr/dts/arm/nxp/nxp_rw6xx_common.dtsi:338 */
				reg = < 0x5000800 0x1000 >;     /* in zephyr/dts/arm/nxp/nxp_rw6xx_common.dtsi:339 */
				status = "okay";                /* in zephyr/dts/arm/nxp/nxp_rw6xx_common.dtsi:340 */
			};

			/* node '/soc/peripheral@50000000/soc_ctrl@5001000' defined in zephyr/dts/arm/nxp/nxp_rw6xx_common.dtsi:343 */
			soc_ctrl: soc_ctrl@5001000 {
				compatible = "nxp,rw-soc-ctrl"; /* in zephyr/dts/arm/nxp/nxp_rw6xx_common.dtsi:344 */
				reg = < 0x5001000 0x1000 >;     /* in zephyr/dts/arm/nxp/nxp_rw6xx_common.dtsi:345 */
				status = "okay";                /* in zephyr/dts/arm/nxp/nxp_rw6xx_common.dtsi:346 */
			};

			/* node '/soc/peripheral@50000000/pint@25000' defined in zephyr/dts/arm/nxp/nxp_rw6xx_common.dtsi:349 */
			pint: pint@25000 {
				compatible = "nxp,pint";                /* in zephyr/dts/arm/nxp/nxp_rw6xx_common.dtsi:350 */
				reg = < 0x25000 0x1000 >;               /* in zephyr/dts/arm/nxp/nxp_rw6xx_common.dtsi:351 */
				interrupt-controller;                   /* in zephyr/dts/arm/nxp/nxp_rw6xx_common.dtsi:352 */
				#interrupt-cells = < 0x1 >;             /* in zephyr/dts/arm/nxp/nxp_rw6xx_common.dtsi:353 */
				#address-cells = < 0x0 >;               /* in zephyr/dts/arm/nxp/nxp_rw6xx_common.dtsi:354 */
				interrupts = < 0x4 0x2 >,
				             < 0x5 0x2 >,
				             < 0x6 0x2 >,
				             < 0x7 0x2 >,
				             < 0x23 0x2 >,
				             < 0x24 0x2 >,
				             < 0x25 0x2 >,
				             < 0x26 0x2 >;              /* in zephyr/dts/arm/nxp/nxp_rw6xx_common.dtsi:355 */
				num-lines = < 0x8 >;                    /* in zephyr/dts/arm/nxp/nxp_rw6xx_common.dtsi:357 */
				num-inputs = < 0x40 >;                  /* in zephyr/dts/arm/nxp/nxp_rw6xx_common.dtsi:358 */
				power-domains = < &peripheral_domain >; /* in zephyr/dts/arm/nxp/nxp_rw6xx_common.dtsi:359 */
			};

			/* node '/soc/peripheral@50000000/nxp_wifi' defined in zephyr/dts/arm/nxp/nxp_rw6xx_common.dtsi:362 */
			imu: nxp_wifi {
				compatible = "nxp,wifi";                /* in zephyr/dts/arm/nxp/nxp_rw6xx_common.dtsi:363 */
				interrupts = < 0x48 0x2 >,
				             < 0x40 0x2 >;              /* in zephyr/dts/arm/nxp/nxp_rw6xx_common.dtsi:365 */
				power-domains = < &peripheral_domain >; /* in zephyr/dts/arm/nxp/nxp_rw6xx_common.dtsi:366 */
			};

			/* node '/soc/peripheral@50000000/dma-controller@104000' defined in zephyr/dts/arm/nxp/nxp_rw6xx_common.dtsi:369 */
			dma0: dma-controller@104000 {
				compatible = "nxp,lpc-dma";             /* in zephyr/dts/arm/nxp/nxp_rw6xx_common.dtsi:370 */
				reg = < 0x104000 0x1000 >;              /* in zephyr/dts/arm/nxp/nxp_rw6xx_common.dtsi:371 */
				interrupts = < 0x1 0x0 >;               /* in zephyr/dts/arm/nxp/nxp_rw6xx_common.dtsi:372 */
				#dma-cells = < 0x1 >;                   /* in zephyr/dts/arm/nxp/nxp_rw6xx_common.dtsi:374 */
				dma-channels = < 0x21 >;                /* in zephyr/dts/arm/nxp/nxp_rw6xx_common.dtsi:375 */
				power-domains = < &peripheral_domain >; /* in zephyr/dts/arm/nxp/nxp_rw6xx_common.dtsi:376 */
				status = "okay";                        /* in zephyr/boards/u-blox/ubx_evk_iris_w1/ubx_evk_iris_w1_common.dtsi:162 */
				phandle = < 0x7 >;                      /* in zephyr/dts/arm/nxp/nxp_rw6xx_common.dtsi:271 */
			};

			/* node '/soc/peripheral@50000000/lcdic@128000' defined in zephyr/dts/arm/nxp/nxp_rw6xx_common.dtsi:379 */
			lcdic: lcdic@128000 {
				compatible = "nxp,lcdic";                              /* in zephyr/dts/arm/nxp/nxp_rw6xx_common.dtsi:380 */
				reg = < 0x128000 0x52 >;                               /* in zephyr/dts/arm/nxp/nxp_rw6xx_common.dtsi:381 */
				interrupts = < 0x3d 0x0 >;                             /* in zephyr/dts/arm/nxp/nxp_rw6xx_common.dtsi:382 */
				status = "disabled";                                   /* in zephyr/dts/arm/nxp/nxp_rw6xx_common.dtsi:383 */
				#address-cells = < 0x1 >;                              /* in zephyr/dts/arm/nxp/nxp_rw6xx_common.dtsi:384 */
				#size-cells = < 0x0 >;                                 /* in zephyr/dts/arm/nxp/nxp_rw6xx_common.dtsi:385 */
				clocks = < &clkctl1 0xe00 >;                           /* in zephyr/dts/arm/nxp/nxp_rw6xx_common.dtsi:386 */
				dmas = < &dma0 0x0 >;                                  /* in zephyr/dts/arm/nxp/nxp_rw6xx_common.dtsi:387 */
				zephyr,disabling-power-states = < &suspend &standby >; /* in zephyr/dts/arm/nxp/nxp_rw6xx_common.dtsi:388 */
				power-domains = < &peripheral_domain >;                /* in zephyr/dts/arm/nxp/nxp_rw6xx_common.dtsi:389 */
			};

			/* node '/soc/peripheral@50000000/rtc@30000' defined in zephyr/dts/arm/nxp/nxp_rw6xx_common.dtsi:392 */
			rtc: rtc@30000 {
				compatible = "nxp,lpc-rtc"; /* in zephyr/dts/arm/nxp/nxp_rw6xx_common.dtsi:393 */
				reg = < 0x30000 0x1000 >;   /* in zephyr/dts/arm/nxp/nxp_rw6xx_common.dtsi:394 */
				interrupts = < 0x20 0x0 >;  /* in zephyr/dts/arm/nxp/nxp_rw6xx_common.dtsi:395 */
				status = "disabled";        /* in zephyr/dts/arm/nxp/nxp_rw6xx_common.dtsi:396 */

				/* node '/soc/peripheral@50000000/rtc@30000/rtc_highres' defined in zephyr/dts/arm/nxp/nxp_rw6xx_common.dtsi:398 */
				rtc_highres: rtc_highres {
					compatible = "nxp,lpc-rtc-highres"; /* in zephyr/dts/arm/nxp/nxp_rw6xx_common.dtsi:399 */
					status = "okay";                    /* in zephyr/boards/u-blox/ubx_evk_iris_w1/ubx_evk_iris_w1_common.dtsi:192 */
					wakeup-source;                      /* in zephyr/boards/u-blox/ubx_evk_iris_w1/ubx_evk_iris_w1_common.dtsi:193 */
					phandle = < 0xf >;                  /* in zephyr/boards/u-blox/ubx_evk_iris_w1/ubx_evk_iris_w1_common.dtsi:177 */
				};
			};

			/* node '/soc/peripheral@50000000/ctimer@28000' defined in zephyr/dts/arm/nxp/nxp_rw6xx_common.dtsi:404 */
			ctimer0: ctimer@28000 {
				compatible = "nxp,lpc-ctimer";          /* in zephyr/dts/arm/nxp/nxp_rw6xx_common.dtsi:405 */
				reg = < 0x28000 0x1000 >;               /* in zephyr/dts/arm/nxp/nxp_rw6xx_common.dtsi:406 */
				interrupts = < 0xa 0x0 >;               /* in zephyr/dts/arm/nxp/nxp_rw6xx_common.dtsi:407 */
				clk-source = < 0x1 >;                   /* in zephyr/dts/arm/nxp/nxp_rw6xx_common.dtsi:409 */
				clocks = < &clkctl1 0x0 >;              /* in zephyr/dts/arm/nxp/nxp_rw6xx_common.dtsi:410 */
				mode = < 0x0 >;                         /* in zephyr/dts/arm/nxp/nxp_rw6xx_common.dtsi:411 */
				input = < 0x0 >;                        /* in zephyr/dts/arm/nxp/nxp_rw6xx_common.dtsi:412 */
				prescale = < 0x0 >;                     /* in zephyr/dts/arm/nxp/nxp_rw6xx_common.dtsi:413 */
				power-domains = < &peripheral_domain >; /* in zephyr/dts/arm/nxp/nxp_rw6xx_common.dtsi:414 */
				status = "okay";                        /* in zephyr/boards/u-blox/ubx_evk_iris_w1/ubx_evk_iris_w1_common.dtsi:170 */
			};

			/* node '/soc/peripheral@50000000/ctimer@29000' defined in zephyr/dts/arm/nxp/nxp_rw6xx_common.dtsi:417 */
			ctimer1: ctimer@29000 {
				compatible = "nxp,lpc-ctimer";          /* in zephyr/dts/arm/nxp/nxp_rw6xx_common.dtsi:418 */
				reg = < 0x29000 0x1000 >;               /* in zephyr/dts/arm/nxp/nxp_rw6xx_common.dtsi:419 */
				interrupts = < 0xb 0x0 >;               /* in zephyr/dts/arm/nxp/nxp_rw6xx_common.dtsi:420 */
				status = "disabled";                    /* in zephyr/dts/arm/nxp/nxp_rw6xx_common.dtsi:421 */
				clk-source = < 0x1 >;                   /* in zephyr/dts/arm/nxp/nxp_rw6xx_common.dtsi:422 */
				clocks = < &clkctl1 0x1 >;              /* in zephyr/dts/arm/nxp/nxp_rw6xx_common.dtsi:423 */
				mode = < 0x0 >;                         /* in zephyr/dts/arm/nxp/nxp_rw6xx_common.dtsi:424 */
				input = < 0x0 >;                        /* in zephyr/dts/arm/nxp/nxp_rw6xx_common.dtsi:425 */
				prescale = < 0x0 >;                     /* in zephyr/dts/arm/nxp/nxp_rw6xx_common.dtsi:426 */
				power-domains = < &peripheral_domain >; /* in zephyr/dts/arm/nxp/nxp_rw6xx_common.dtsi:427 */
			};

			/* node '/soc/peripheral@50000000/ctimer@2a000' defined in zephyr/dts/arm/nxp/nxp_rw6xx_common.dtsi:430 */
			ctimer2: ctimer@2a000 {
				compatible = "nxp,lpc-ctimer";          /* in zephyr/dts/arm/nxp/nxp_rw6xx_common.dtsi:431 */
				reg = < 0x2a000 0x1000 >;               /* in zephyr/dts/arm/nxp/nxp_rw6xx_common.dtsi:432 */
				interrupts = < 0x27 0x0 >;              /* in zephyr/dts/arm/nxp/nxp_rw6xx_common.dtsi:433 */
				status = "disabled";                    /* in zephyr/dts/arm/nxp/nxp_rw6xx_common.dtsi:434 */
				clk-source = < 0x1 >;                   /* in zephyr/dts/arm/nxp/nxp_rw6xx_common.dtsi:435 */
				clocks = < &clkctl1 0x2 >;              /* in zephyr/dts/arm/nxp/nxp_rw6xx_common.dtsi:436 */
				mode = < 0x0 >;                         /* in zephyr/dts/arm/nxp/nxp_rw6xx_common.dtsi:437 */
				input = < 0x0 >;                        /* in zephyr/dts/arm/nxp/nxp_rw6xx_common.dtsi:438 */
				prescale = < 0x0 >;                     /* in zephyr/dts/arm/nxp/nxp_rw6xx_common.dtsi:439 */
				power-domains = < &peripheral_domain >; /* in zephyr/dts/arm/nxp/nxp_rw6xx_common.dtsi:440 */
			};

			/* node '/soc/peripheral@50000000/ctimer@2b000' defined in zephyr/dts/arm/nxp/nxp_rw6xx_common.dtsi:443 */
			ctimer3: ctimer@2b000 {
				compatible = "nxp,lpc-ctimer";          /* in zephyr/dts/arm/nxp/nxp_rw6xx_common.dtsi:444 */
				reg = < 0x2b000 0x1000 >;               /* in zephyr/dts/arm/nxp/nxp_rw6xx_common.dtsi:445 */
				interrupts = < 0xd 0x0 >;               /* in zephyr/dts/arm/nxp/nxp_rw6xx_common.dtsi:446 */
				status = "disabled";                    /* in zephyr/dts/arm/nxp/nxp_rw6xx_common.dtsi:447 */
				clk-source = < 0x1 >;                   /* in zephyr/dts/arm/nxp/nxp_rw6xx_common.dtsi:448 */
				clocks = < &clkctl1 0x3 >;              /* in zephyr/dts/arm/nxp/nxp_rw6xx_common.dtsi:449 */
				mode = < 0x0 >;                         /* in zephyr/dts/arm/nxp/nxp_rw6xx_common.dtsi:450 */
				input = < 0x0 >;                        /* in zephyr/dts/arm/nxp/nxp_rw6xx_common.dtsi:451 */
				prescale = < 0x0 >;                     /* in zephyr/dts/arm/nxp/nxp_rw6xx_common.dtsi:452 */
				power-domains = < &peripheral_domain >; /* in zephyr/dts/arm/nxp/nxp_rw6xx_common.dtsi:453 */
			};

			/* node '/soc/peripheral@50000000/pwm@146000' defined in zephyr/dts/arm/nxp/nxp_rw6xx_common.dtsi:456 */
			sctimer: pwm@146000 {
				compatible = "nxp,sctimer-pwm";         /* in zephyr/dts/arm/nxp/nxp_rw6xx_common.dtsi:457 */
				reg = < 0x146000 0x1000 >;              /* in zephyr/dts/arm/nxp/nxp_rw6xx_common.dtsi:458 */
				interrupts = < 0xc 0x0 >;               /* in zephyr/dts/arm/nxp/nxp_rw6xx_common.dtsi:459 */
				clocks = < &clkctl1 0x900 >;            /* in zephyr/dts/arm/nxp/nxp_rw6xx_common.dtsi:460 */
				prescaler = < 0x8 >;                    /* in zephyr/dts/arm/nxp/nxp_rw6xx_common.dtsi:462 */
				#pwm-cells = < 0x3 >;                   /* in zephyr/dts/arm/nxp/nxp_rw6xx_common.dtsi:463 */
				power-domains = < &peripheral_domain >; /* in zephyr/dts/arm/nxp/nxp_rw6xx_common.dtsi:464 */
				status = "okay";                        /* in zephyr/boards/u-blox/ubx_evk_iris_w1/ubx_evk_iris_w1_common.dtsi:185 */
				pinctrl-0 = < &pinmux_pwm0 >;           /* in zephyr/boards/u-blox/ubx_evk_iris_w1/ubx_evk_iris_w1_common.dtsi:186 */
				pinctrl-names = "default";              /* in zephyr/boards/u-blox/ubx_evk_iris_w1/ubx_evk_iris_w1_common.dtsi:187 */
			};

			/* node '/soc/peripheral@50000000/mrt@2d000' defined in zephyr/dts/arm/nxp/nxp_rw6xx_common.dtsi:467 */
			mrt0: mrt@2d000 {
				compatible = "nxp,mrt";                 /* in zephyr/dts/arm/nxp/nxp_rw6xx_common.dtsi:468 */
				reg = < 0x2d000 0x100 >;                /* in zephyr/dts/arm/nxp/nxp_rw6xx_common.dtsi:469 */
				interrupts = < 0x9 0x0 >;               /* in zephyr/dts/arm/nxp/nxp_rw6xx_common.dtsi:470 */
				num-channels = < 0x4 >;                 /* in zephyr/dts/arm/nxp/nxp_rw6xx_common.dtsi:471 */
				num-bits = < 0x18 >;                    /* in zephyr/dts/arm/nxp/nxp_rw6xx_common.dtsi:472 */
				clocks = < &clkctl1 0xb00 >;            /* in zephyr/dts/arm/nxp/nxp_rw6xx_common.dtsi:473 */
				resets = < &rstctl1 0x20008 >;          /* in zephyr/dts/arm/nxp/nxp_rw6xx_common.dtsi:474 */
				#address-cells = < 0x1 >;               /* in zephyr/dts/arm/nxp/nxp_rw6xx_common.dtsi:475 */
				#size-cells = < 0x0 >;                  /* in zephyr/dts/arm/nxp/nxp_rw6xx_common.dtsi:476 */
				power-domains = < &peripheral_domain >; /* in zephyr/dts/arm/nxp/nxp_rw6xx_common.dtsi:477 */

				/* node '/soc/peripheral@50000000/mrt@2d000/mrt0_channel@0' defined in zephyr/dts/arm/nxp/nxp_rw6xx_common.dtsi:479 */
				mrt0_channel0: mrt0_channel@0 {
					compatible = "nxp,mrt-channel"; /* in zephyr/dts/arm/nxp/nxp_rw6xx_common.dtsi:480 */
					reg = < 0x0 >;                  /* in zephyr/dts/arm/nxp/nxp_rw6xx_common.dtsi:481 */
					status = "okay";                /* in zephyr/boards/u-blox/ubx_evk_iris_w1/ubx_evk_iris_w1_common.dtsi:166 */
				};

				/* node '/soc/peripheral@50000000/mrt@2d000/mrt0_channel@1' defined in zephyr/dts/arm/nxp/nxp_rw6xx_common.dtsi:485 */
				mrt0_channel1: mrt0_channel@1 {
					compatible = "nxp,mrt-channel"; /* in zephyr/dts/arm/nxp/nxp_rw6xx_common.dtsi:486 */
					reg = < 0x1 >;                  /* in zephyr/dts/arm/nxp/nxp_rw6xx_common.dtsi:487 */
					status = "disabled";            /* in zephyr/dts/arm/nxp/nxp_rw6xx_common.dtsi:488 */
				};

				/* node '/soc/peripheral@50000000/mrt@2d000/mrt0_channel@2' defined in zephyr/dts/arm/nxp/nxp_rw6xx_common.dtsi:491 */
				mrt0_channel2: mrt0_channel@2 {
					compatible = "nxp,mrt-channel"; /* in zephyr/dts/arm/nxp/nxp_rw6xx_common.dtsi:492 */
					reg = < 0x2 >;                  /* in zephyr/dts/arm/nxp/nxp_rw6xx_common.dtsi:493 */
					status = "disabled";            /* in zephyr/dts/arm/nxp/nxp_rw6xx_common.dtsi:494 */
				};

				/* node '/soc/peripheral@50000000/mrt@2d000/mrt0_channel@3' defined in zephyr/dts/arm/nxp/nxp_rw6xx_common.dtsi:497 */
				mrt0_channel3: mrt0_channel@3 {
					compatible = "nxp,mrt-channel"; /* in zephyr/dts/arm/nxp/nxp_rw6xx_common.dtsi:498 */
					reg = < 0x3 >;                  /* in zephyr/dts/arm/nxp/nxp_rw6xx_common.dtsi:499 */
					status = "disabled";            /* in zephyr/dts/arm/nxp/nxp_rw6xx_common.dtsi:500 */
				};
			};

			/* node '/soc/peripheral@50000000/mrt@3f000' defined in zephyr/dts/arm/nxp/nxp_rw6xx_common.dtsi:504 */
			mrt1: mrt@3f000 {
				compatible = "nxp,mrt";                 /* in zephyr/dts/arm/nxp/nxp_rw6xx_common.dtsi:505 */
				reg = < 0x3f000 0x100 >;                /* in zephyr/dts/arm/nxp/nxp_rw6xx_common.dtsi:506 */
				interrupts = < 0x17 0x0 >;              /* in zephyr/dts/arm/nxp/nxp_rw6xx_common.dtsi:507 */
				num-channels = < 0x4 >;                 /* in zephyr/dts/arm/nxp/nxp_rw6xx_common.dtsi:508 */
				num-bits = < 0x18 >;                    /* in zephyr/dts/arm/nxp/nxp_rw6xx_common.dtsi:509 */
				clocks = < &clkctl1 0xb01 >;            /* in zephyr/dts/arm/nxp/nxp_rw6xx_common.dtsi:510 */
				resets = < &rstctl0 0x2001a >;          /* in zephyr/dts/arm/nxp/nxp_rw6xx_common.dtsi:511 */
				#address-cells = < 0x1 >;               /* in zephyr/dts/arm/nxp/nxp_rw6xx_common.dtsi:512 */
				#size-cells = < 0x0 >;                  /* in zephyr/dts/arm/nxp/nxp_rw6xx_common.dtsi:513 */
				power-domains = < &peripheral_domain >; /* in zephyr/dts/arm/nxp/nxp_rw6xx_common.dtsi:514 */

				/* node '/soc/peripheral@50000000/mrt@3f000/mrt1_channel@0' defined in zephyr/dts/arm/nxp/nxp_rw6xx_common.dtsi:516 */
				mrt1_channel0: mrt1_channel@0 {
					compatible = "nxp,mrt-channel"; /* in zephyr/dts/arm/nxp/nxp_rw6xx_common.dtsi:517 */
					reg = < 0x0 >;                  /* in zephyr/dts/arm/nxp/nxp_rw6xx_common.dtsi:518 */
					status = "disabled";            /* in zephyr/dts/arm/nxp/nxp_rw6xx_common.dtsi:519 */
				};

				/* node '/soc/peripheral@50000000/mrt@3f000/mrt1_channel@1' defined in zephyr/dts/arm/nxp/nxp_rw6xx_common.dtsi:522 */
				mrt1_channel1: mrt1_channel@1 {
					compatible = "nxp,mrt-channel"; /* in zephyr/dts/arm/nxp/nxp_rw6xx_common.dtsi:523 */
					reg = < 0x1 >;                  /* in zephyr/dts/arm/nxp/nxp_rw6xx_common.dtsi:524 */
					status = "disabled";            /* in zephyr/dts/arm/nxp/nxp_rw6xx_common.dtsi:525 */
				};

				/* node '/soc/peripheral@50000000/mrt@3f000/mrt1_channel@2' defined in zephyr/dts/arm/nxp/nxp_rw6xx_common.dtsi:528 */
				mrt1_channel2: mrt1_channel@2 {
					compatible = "nxp,mrt-channel"; /* in zephyr/dts/arm/nxp/nxp_rw6xx_common.dtsi:529 */
					reg = < 0x2 >;                  /* in zephyr/dts/arm/nxp/nxp_rw6xx_common.dtsi:530 */
					status = "disabled";            /* in zephyr/dts/arm/nxp/nxp_rw6xx_common.dtsi:531 */
				};

				/* node '/soc/peripheral@50000000/mrt@3f000/mrt1_channel@3' defined in zephyr/dts/arm/nxp/nxp_rw6xx_common.dtsi:534 */
				mrt1_channel3: mrt1_channel@3 {
					compatible = "nxp,mrt-channel"; /* in zephyr/dts/arm/nxp/nxp_rw6xx_common.dtsi:535 */
					reg = < 0x3 >;                  /* in zephyr/dts/arm/nxp/nxp_rw6xx_common.dtsi:536 */
					status = "disabled";            /* in zephyr/dts/arm/nxp/nxp_rw6xx_common.dtsi:537 */
				};
			};

			/* node '/soc/peripheral@50000000/dmic@121000' defined in zephyr/dts/arm/nxp/nxp_rw6xx_common.dtsi:541 */
			dmic0: dmic@121000 {
				#address-cells = < 0x1 >;               /* in zephyr/dts/arm/nxp/nxp_rw6xx_common.dtsi:542 */
				#size-cells = < 0x0 >;                  /* in zephyr/dts/arm/nxp/nxp_rw6xx_common.dtsi:543 */
				compatible = "nxp,dmic";                /* in zephyr/dts/arm/nxp/nxp_rw6xx_common.dtsi:544 */
				reg = < 0x121000 0x1000 >;              /* in zephyr/dts/arm/nxp/nxp_rw6xx_common.dtsi:545 */
				interrupts = < 0x19 0x0 >;              /* in zephyr/dts/arm/nxp/nxp_rw6xx_common.dtsi:546 */
				status = "disabled";                    /* in zephyr/dts/arm/nxp/nxp_rw6xx_common.dtsi:547 */
				clocks = < &clkctl1 0xa00 >;            /* in zephyr/dts/arm/nxp/nxp_rw6xx_common.dtsi:548 */
				power-domains = < &peripheral_domain >; /* in zephyr/dts/arm/nxp/nxp_rw6xx_common.dtsi:549 */

				/* node '/soc/peripheral@50000000/dmic@121000/dmic-channel@0' defined in zephyr/dts/arm/nxp/nxp_rw6xx_common.dtsi:551 */
				pdmc0: dmic-channel@0 {
					reg = < 0x0 >;         /* in zephyr/dts/arm/nxp/nxp_rw6xx_common.dtsi:552 */
					dmas = < &dma0 0x10 >; /* in zephyr/dts/arm/nxp/nxp_rw6xx_common.dtsi:553 */
					status = "disabled";   /* in zephyr/dts/arm/nxp/nxp_rw6xx_common.dtsi:554 */
				};

				/* node '/soc/peripheral@50000000/dmic@121000/dmic-channel@1' defined in zephyr/dts/arm/nxp/nxp_rw6xx_common.dtsi:557 */
				pdmc1: dmic-channel@1 {
					reg = < 0x1 >;         /* in zephyr/dts/arm/nxp/nxp_rw6xx_common.dtsi:558 */
					dmas = < &dma0 0x11 >; /* in zephyr/dts/arm/nxp/nxp_rw6xx_common.dtsi:559 */
					status = "disabled";   /* in zephyr/dts/arm/nxp/nxp_rw6xx_common.dtsi:560 */
				};

				/* node '/soc/peripheral@50000000/dmic@121000/dmic-channel@2' defined in zephyr/dts/arm/nxp/nxp_rw6xx_common.dtsi:563 */
				pdmc2: dmic-channel@2 {
					reg = < 0x2 >;         /* in zephyr/dts/arm/nxp/nxp_rw6xx_common.dtsi:564 */
					dmas = < &dma0 0x12 >; /* in zephyr/dts/arm/nxp/nxp_rw6xx_common.dtsi:565 */
					status = "disabled";   /* in zephyr/dts/arm/nxp/nxp_rw6xx_common.dtsi:566 */
				};

				/* node '/soc/peripheral@50000000/dmic@121000/dmic-channel@3' defined in zephyr/dts/arm/nxp/nxp_rw6xx_common.dtsi:569 */
				pdmc3: dmic-channel@3 {
					reg = < 0x3 >;         /* in zephyr/dts/arm/nxp/nxp_rw6xx_common.dtsi:570 */
					dmas = < &dma0 0x13 >; /* in zephyr/dts/arm/nxp/nxp_rw6xx_common.dtsi:571 */
					status = "disabled";   /* in zephyr/dts/arm/nxp/nxp_rw6xx_common.dtsi:572 */
				};
			};

			/* node '/soc/peripheral@50000000/gau' defined in zephyr/dts/arm/nxp/nxp_rw6xx_common.dtsi:576 */
			gau {
				ranges;                   /* in zephyr/dts/arm/nxp/nxp_rw6xx_common.dtsi:577 */
				#address-cells = < 0x1 >; /* in zephyr/dts/arm/nxp/nxp_rw6xx_common.dtsi:578 */
				#size-cells = < 0x1 >;    /* in zephyr/dts/arm/nxp/nxp_rw6xx_common.dtsi:579 */

				/* node '/soc/peripheral@50000000/gau/gau_adc0@38000' defined in zephyr/dts/arm/nxp/nxp_rw6xx_common.dtsi:581 */
				adc0: gau_adc0@38000 {
					compatible = "nxp,gau-adc";             /* in zephyr/dts/arm/nxp/nxp_rw6xx_common.dtsi:582 */
					reg = < 0x38000 0x100 >;                /* in zephyr/dts/arm/nxp/nxp_rw6xx_common.dtsi:583 */
					interrupts = < 0x70 0x0 >;              /* in zephyr/dts/arm/nxp/nxp_rw6xx_common.dtsi:584 */
					status = "disabled";                    /* in zephyr/dts/arm/nxp/nxp_rw6xx_common.dtsi:585 */
					#io-channel-cells = < 0x1 >;            /* in zephyr/dts/arm/nxp/nxp_rw6xx_common.dtsi:586 */
					power-domains = < &peripheral_domain >; /* in zephyr/dts/arm/nxp/nxp_rw6xx_common.dtsi:587 */
				};

				/* node '/soc/peripheral@50000000/gau/gau_adc1@38100' defined in zephyr/dts/arm/nxp/nxp_rw6xx_common.dtsi:590 */
				adc1: gau_adc1@38100 {
					compatible = "nxp,gau-adc";             /* in zephyr/dts/arm/nxp/nxp_rw6xx_common.dtsi:591 */
					reg = < 0x38100 0x100 >;                /* in zephyr/dts/arm/nxp/nxp_rw6xx_common.dtsi:592 */
					interrupts = < 0x6f 0x0 >;              /* in zephyr/dts/arm/nxp/nxp_rw6xx_common.dtsi:593 */
					status = "disabled";                    /* in zephyr/dts/arm/nxp/nxp_rw6xx_common.dtsi:594 */
					#io-channel-cells = < 0x1 >;            /* in zephyr/dts/arm/nxp/nxp_rw6xx_common.dtsi:595 */
					power-domains = < &peripheral_domain >; /* in zephyr/dts/arm/nxp/nxp_rw6xx_common.dtsi:596 */
				};

				/* node '/soc/peripheral@50000000/gau/dac@38200' defined in zephyr/dts/arm/nxp/nxp_rw6xx_common.dtsi:599 */
				dac0: dac@38200 {
					compatible = "nxp,gau-dac";             /* in zephyr/dts/arm/nxp/nxp_rw6xx_common.dtsi:600 */
					reg = < 0x38200 0x30 >;                 /* in zephyr/dts/arm/nxp/nxp_rw6xx_common.dtsi:601 */
					interrupts = < 0x6c 0x0 >;              /* in zephyr/dts/arm/nxp/nxp_rw6xx_common.dtsi:602 */
					status = "disabled";                    /* in zephyr/dts/arm/nxp/nxp_rw6xx_common.dtsi:603 */
					#io-channel-cells = < 0x0 >;            /* in zephyr/dts/arm/nxp/nxp_rw6xx_common.dtsi:604 */
					power-domains = < &peripheral_domain >; /* in zephyr/dts/arm/nxp/nxp_rw6xx_common.dtsi:605 */
				};
			};

			/* node '/soc/peripheral@50000000/timers@13b000' defined in zephyr/dts/arm/nxp/nxp_rw6xx_common.dtsi:609 */
			os_timer: timers@13b000 {
				compatible = "nxp,os-timer";           /* in zephyr/dts/arm/nxp/nxp_rw6xx_common.dtsi:610 */
				reg = < 0x13b000 0x1000 >;             /* in zephyr/dts/arm/nxp/nxp_rw6xx_common.dtsi:611 */
				interrupts = < 0x29 0x0 >;             /* in zephyr/dts/arm/nxp/nxp_rw6xx_common.dtsi:612 */
				status = "okay";                       /* in zephyr/boards/u-blox/ubx_evk_iris_w1/ubx_evk_iris_w1_common.dtsi:175 */
				wakeup-source;                         /* in zephyr/boards/u-blox/ubx_evk_iris_w1/ubx_evk_iris_w1_common.dtsi:176 */
				deep-sleep-counter = < &rtc_highres >; /* in zephyr/boards/u-blox/ubx_evk_iris_w1/ubx_evk_iris_w1_common.dtsi:177 */
			};

			/* node '/soc/peripheral@50000000/nbu' defined in zephyr/dts/arm/nxp/nxp_rw6xx_common.dtsi:616 */
			nbu: nbu {
				compatible = "nxp,nbu";         /* in zephyr/dts/arm/nxp/nxp_rw6xx_common.dtsi:617 */
				interrupts = < 0x5a 0x2 >,
				             < 0x52 0x2 >;      /* in zephyr/dts/arm/nxp/nxp_rw6xx_common.dtsi:618 */
				interrupt-names = "nbu_rx_int",
				                  "wakeup_int"; /* in zephyr/dts/arm/nxp/nxp_rw6xx_common.dtsi:619 */
				status = "okay";                /* in zephyr/boards/u-blox/ubx_evk_iris_w1/ubx_evk_iris_w1_common.dtsi:197 */
				wakeup-source;                  /* in zephyr/boards/u-blox/ubx_evk_iris_w1/ubx_evk_iris_w1_common.dtsi:198 */
			};

			/* node '/soc/peripheral@50000000/hci_ble' defined in zephyr/dts/arm/nxp/nxp_rw6xx_common.dtsi:622 */
			hci: hci_ble {
				compatible = "nxp,hci-ble";             /* in zephyr/dts/arm/nxp/nxp_rw6xx_common.dtsi:623 */
				power-domains = < &peripheral_domain >; /* in zephyr/dts/arm/nxp/nxp_rw6xx_common.dtsi:624 */
				status = "okay";                        /* in zephyr/boards/u-blox/ubx_evk_iris_w1/ubx_evk_iris_w1_common.dtsi:153 */
				wakeup-source;                          /* in zephyr/boards/u-blox/ubx_evk_iris_w1/ubx_evk_iris_w1_common.dtsi:154 */
			};

			/* node '/soc/peripheral@50000000/hdlc_rcp_if' defined in zephyr/dts/arm/nxp/nxp_rw6xx_common.dtsi:627 */
			hdlc_rcp_if: hdlc_rcp_if {
				compatible = "nxp,hdlc-rcp-if";         /* in zephyr/dts/arm/nxp/nxp_rw6xx_common.dtsi:628 */
				interrupts = < 0x5a 0x2 >,
				             < 0x52 0x2 >;              /* in zephyr/dts/arm/nxp/nxp_rw6xx_common.dtsi:629 */
				interrupt-names = "hdlc_rcp_if_int",
				                  "wakeup_int";         /* in zephyr/dts/arm/nxp/nxp_rw6xx_common.dtsi:630 */
				power-domains = < &peripheral_domain >; /* in zephyr/dts/arm/nxp/nxp_rw6xx_common.dtsi:631 */
			};

			/* node '/soc/peripheral@50000000/enet@138000' defined in zephyr/dts/arm/nxp/nxp_rw6xx_common.dtsi:634 */
			enet: enet@138000 {
				compatible = "nxp,enet";     /* in zephyr/dts/arm/nxp/nxp_rw6xx_common.dtsi:635 */
				reg = < 0x138000 0x700 >;    /* in zephyr/dts/arm/nxp/nxp_rw6xx_common.dtsi:636 */
				clocks = < &clkctl1 0xd80 >; /* in zephyr/dts/arm/nxp/nxp_rw6xx_common.dtsi:637 */

				/* node '/soc/peripheral@50000000/enet@138000/ethernet' defined in zephyr/dts/arm/nxp/nxp_rw6xx_common.dtsi:639 */
				enet_mac: ethernet {
					compatible = "nxp,enet-mac";            /* in zephyr/dts/arm/nxp/nxp_rw6xx_common.dtsi:640 */
					interrupts = < 0x73 0x0 >;              /* in zephyr/dts/arm/nxp/nxp_rw6xx_common.dtsi:641 */
					interrupt-names = "COMMON";             /* in zephyr/dts/arm/nxp/nxp_rw6xx_common.dtsi:642 */
					nxp,mdio = < &enet_mdio >;              /* in zephyr/dts/arm/nxp/nxp_rw6xx_common.dtsi:643 */
					ptp-clock = < &enet_ptp_clock >;        /* in zephyr/dts/arm/nxp/nxp_rw6xx_common.dtsi:644 */
					status = "disabled";                    /* in zephyr/dts/arm/nxp/nxp_rw6xx_common.dtsi:645 */
					power-domains = < &peripheral_domain >; /* in zephyr/dts/arm/nxp/nxp_rw6xx_common.dtsi:646 */
				};

				/* node '/soc/peripheral@50000000/enet@138000/mdio' defined in zephyr/dts/arm/nxp/nxp_rw6xx_common.dtsi:649 */
				enet_mdio: mdio {
					compatible = "nxp,enet-mdio";           /* in zephyr/dts/arm/nxp/nxp_rw6xx_common.dtsi:650 */
					status = "disabled";                    /* in zephyr/dts/arm/nxp/nxp_rw6xx_common.dtsi:651 */
					#address-cells = < 0x1 >;               /* in zephyr/dts/arm/nxp/nxp_rw6xx_common.dtsi:652 */
					#size-cells = < 0x0 >;                  /* in zephyr/dts/arm/nxp/nxp_rw6xx_common.dtsi:653 */
					power-domains = < &peripheral_domain >; /* in zephyr/dts/arm/nxp/nxp_rw6xx_common.dtsi:654 */
					phandle = < 0x10 >;                     /* in zephyr/dts/arm/nxp/nxp_rw6xx_common.dtsi:643 */
				};

				/* node '/soc/peripheral@50000000/enet@138000/ptp-clock' defined in zephyr/dts/arm/nxp/nxp_rw6xx_common.dtsi:657 */
				enet_ptp_clock: ptp-clock {
					compatible = "nxp,enet-ptp-clock";      /* in zephyr/dts/arm/nxp/nxp_rw6xx_common.dtsi:658 */
					interrupts = < 0x74 0x0 >;              /* in zephyr/dts/arm/nxp/nxp_rw6xx_common.dtsi:659 */
					status = "disabled";                    /* in zephyr/dts/arm/nxp/nxp_rw6xx_common.dtsi:660 */
					clocks = < &clkctl1 0xd81 >;            /* in zephyr/dts/arm/nxp/nxp_rw6xx_common.dtsi:661 */
					power-domains = < &peripheral_domain >; /* in zephyr/dts/arm/nxp/nxp_rw6xx_common.dtsi:662 */
					phandle = < 0x11 >;                     /* in zephyr/dts/arm/nxp/nxp_rw6xx_common.dtsi:644 */
				};
			};
		};
	};

	/* node '/cpus' defined in zephyr/dts/arm/nxp/nxp_rw6xx_common.dtsi:24 */
	cpus {
		#address-cells = < 0x1 >; /* in zephyr/dts/arm/nxp/nxp_rw6xx_common.dtsi:25 */
		#size-cells = < 0x0 >;    /* in zephyr/dts/arm/nxp/nxp_rw6xx_common.dtsi:26 */

		/* node '/cpus/cpu@0' defined in zephyr/dts/arm/nxp/nxp_rw6xx_common.dtsi:28 */
		cpu0: cpu@0 {
			compatible = "arm,cortex-m33f";                 /* in zephyr/dts/arm/nxp/nxp_rw6xx_common.dtsi:29 */
			reg = < 0x0 >;                                  /* in zephyr/dts/arm/nxp/nxp_rw6xx_common.dtsi:30 */
			#address-cells = < 0x1 >;                       /* in zephyr/dts/arm/nxp/nxp_rw6xx_common.dtsi:31 */
			#size-cells = < 0x1 >;                          /* in zephyr/dts/arm/nxp/nxp_rw6xx_common.dtsi:32 */
			cpu-power-states = < &idle &suspend &standby >; /* in zephyr/dts/arm/nxp/nxp_rw6xx_common.dtsi:33 */

			/* node '/cpus/cpu@0/mpu@e000ed90' defined in zephyr/dts/arm/nxp/nxp_rw6xx_common.dtsi:35 */
			mpu: mpu@e000ed90 {
				compatible = "arm,armv8m-mpu"; /* in zephyr/dts/arm/nxp/nxp_rw6xx_common.dtsi:36 */
				reg = < 0xe000ed90 0x40 >;     /* in zephyr/dts/arm/nxp/nxp_rw6xx_common.dtsi:37 */
			};
		};

		/* node '/cpus/power-states' defined in zephyr/dts/arm/nxp/nxp_rw6xx_common.dtsi:41 */
		power-states {

			/* node '/cpus/power-states/idle' defined in zephyr/dts/arm/nxp/nxp_rw6xx_common.dtsi:43 */
			idle: idle {
				compatible = "zephyr,power-state"; /* in zephyr/dts/arm/nxp/nxp_rw6xx_common.dtsi:44 */
				power-state-name = "runtime-idle"; /* in zephyr/dts/arm/nxp/nxp_rw6xx_common.dtsi:45 */
				min-residency-us = < 0x3c >;       /* in zephyr/dts/arm/nxp/nxp_rw6xx_common.dtsi:46 */
				exit-latency-us = < 0x26 >;        /* in zephyr/dts/arm/nxp/nxp_rw6xx_common.dtsi:47 */
				phandle = < 0x12 >;                /* in zephyr/dts/arm/nxp/nxp_rw6xx_common.dtsi:33 */
			};

			/* node '/cpus/power-states/suspend' defined in zephyr/dts/arm/nxp/nxp_rw6xx_common.dtsi:51 */
			suspend: suspend {
				compatible = "nxp,pdcfg-power",
				             "zephyr,power-state";    /* in zephyr/dts/arm/nxp/nxp_rw6xx_common.dtsi:52 */
				power-state-name = "suspend-to-idle"; /* in zephyr/dts/arm/nxp/nxp_rw6xx_common.dtsi:53 */
				min-residency-us = < 0x258 >;         /* in zephyr/dts/arm/nxp/nxp_rw6xx_common.dtsi:54 */
				exit-latency-us = < 0x26 >;           /* in zephyr/dts/arm/nxp/nxp_rw6xx_common.dtsi:55 */
				deep-sleep-config = < 0x180000 >,
				                    < 0x0 >,
				                    < 0x4 >,
				                    < 0x100 >,
				                    < 0x0 >;          /* in zephyr/dts/arm/nxp/nxp_rw6xx_common.dtsi:56 */
				phandle = < 0x8 >;                    /* in zephyr/dts/arm/nxp/nxp_rw6xx_common.dtsi:273 */
			};

			/* node '/cpus/power-states/standby' defined in zephyr/dts/arm/nxp/nxp_rw6xx_common.dtsi:64 */
			standby: standby {
				compatible = "nxp,pdcfg-power",
				             "zephyr,power-state"; /* in zephyr/dts/arm/nxp/nxp_rw6xx_common.dtsi:65 */
				power-state-name = "standby";      /* in zephyr/dts/arm/nxp/nxp_rw6xx_common.dtsi:66 */
				min-residency-us = < 0x52080 >;    /* in zephyr/dts/arm/nxp/nxp_rw6xx_common.dtsi:67 */
				exit-latency-us = < 0x36b0 >;      /* in zephyr/dts/arm/nxp/nxp_rw6xx_common.dtsi:68 */
				deep-sleep-config = < 0x180000 >,
				                    < 0x0 >,
				                    < 0x4 >,
				                    < 0x100 >,
				                    < 0x0 >;       /* in zephyr/dts/arm/nxp/nxp_rw6xx_common.dtsi:69 */
				status = "disabled";               /* in zephyr/dts/arm/nxp/nxp_rw6xx_common.dtsi:74 */
				phandle = < 0x9 >;                 /* in zephyr/dts/arm/nxp/nxp_rw6xx_common.dtsi:273 */
			};
		};
	};

	/* node '/sram@41380000' defined in zephyr/dts/arm/nxp/nxp_rw6xx_common.dtsi:79 */
	smu1: sram@41380000 {
		ranges = < 0x0 0x41380000 0x7f800 >; /* in zephyr/dts/arm/nxp/nxp_rw6xx_common.dtsi:80 */
		#address-cells = < 0x1 >;            /* in zephyr/dts/arm/nxp/nxp_rw6xx_common.dtsi:123 */
		#size-cells = < 0x1 >;               /* in zephyr/dts/arm/nxp/nxp_rw6xx_common.dtsi:124 */

		/* node '/sram@41380000/memory@0' defined in zephyr/dts/arm/nxp/nxp_rw6xx_common.dtsi:126 */
		smu1_data: memory@0 {
			compatible = "zephyr,memory-region",
			             "mmio-sram";            /* in zephyr/dts/arm/nxp/nxp_rw6xx_common.dtsi:127 */
			reg = < 0x0 0x7f800 >;               /* in zephyr/dts/arm/nxp/nxp_rw6xx_common.dtsi:128 */
			zephyr,memory-region = "SMU1";       /* in zephyr/dts/arm/nxp/nxp_rw6xx_common.dtsi:129 */
			zephyr,memory-attr = < 0x100000 >;   /* in zephyr/dts/arm/nxp/nxp_rw6xx_common.dtsi:130 */
		};
	};

	/* node '/sram@443C0000' defined in zephyr/dts/arm/nxp/nxp_rw6xx_common.dtsi:83 */
	smu2: sram@443C0000 {
		ranges = < 0x0 0x443c0000 0x23000 >; /* in zephyr/dts/arm/nxp/nxp_rw6xx_common.dtsi:84 */
		#address-cells = < 0x1 >;            /* in zephyr/dts/arm/nxp/nxp_rw6xx_common.dtsi:135 */
		#size-cells = < 0x1 >;               /* in zephyr/dts/arm/nxp/nxp_rw6xx_common.dtsi:136 */

		/* node '/sram@443C0000/memory@0' defined in zephyr/dts/arm/nxp/nxp_rw6xx_common.dtsi:138 */
		smu2_data: memory@0 {
			compatible = "zephyr,memory-region",
			             "mmio-sram";            /* in zephyr/dts/arm/nxp/nxp_rw6xx_common.dtsi:139 */
			reg = < 0x0 0x23000 >;               /* in zephyr/dts/arm/nxp/nxp_rw6xx_common.dtsi:140 */
			zephyr,memory-region = "SMU2";       /* in zephyr/dts/arm/nxp/nxp_rw6xx_common.dtsi:141 */
			zephyr,memory-attr = < 0x100000 >;   /* in zephyr/dts/arm/nxp/nxp_rw6xx_common.dtsi:142 */
		};
	};

	/* node '/peripheral-domain' defined in zephyr/dts/arm/nxp/nxp_rw6xx_common.dtsi:87 */
	peripheral_domain: peripheral-domain {
		compatible = "power-domain-soc-state-change";          /* in zephyr/dts/arm/nxp/nxp_rw6xx_common.dtsi:88 */
		#power-domain-cells = < 0x0 >;                         /* in zephyr/dts/arm/nxp/nxp_rw6xx_common.dtsi:89 */
		zephyr,disabling-power-states = < &suspend &standby >; /* in zephyr/dts/arm/nxp/nxp_rw6xx_common.dtsi:90 */
		onoff-power-states = < &standby >;                     /* in zephyr/dts/arm/nxp/nxp_rw6xx_common.dtsi:91 */
		phandle = < 0x3 >;                                     /* in zephyr/dts/arm/nxp/nxp_rw6xx_common.dtsi:208 */
	};

	/* node '/xtal32' defined in zephyr/dts/arm/nxp/nxp_rw6xx_common.dtsi:94 */
	xtal32: xtal32 {
		compatible = "fixed-clock";   /* in zephyr/dts/arm/nxp/nxp_rw6xx_common.dtsi:95 */
		clock-frequency = < 0x8000 >; /* in zephyr/dts/arm/nxp/nxp_rw6xx_common.dtsi:96 */
		#clock-cells = < 0x0 >;       /* in zephyr/dts/arm/nxp/nxp_rw6xx_common.dtsi:97 */
		status = "disabled";          /* in zephyr/boards/u-blox/ubx_evk_iris_w1/ubx_evk_iris_w1_common.dtsi:202 */
	};

	/* node '/rgb_leds' defined in zephyr/boards/u-blox/ubx_evk_iris_w1/ubx_evk_iris_w1_common.dtsi:37 */
	rgb_leds {
		compatible = "gpio-leds"; /* in zephyr/boards/u-blox/ubx_evk_iris_w1/ubx_evk_iris_w1_common.dtsi:38 */

		/* node '/rgb_leds/led_1' defined in zephyr/boards/u-blox/ubx_evk_iris_w1/ubx_evk_iris_w1_common.dtsi:40 */
		rgb_blue: led_1 {
			gpios = < &hsgpio1 0xa 0x1 >; /* in zephyr/boards/u-blox/ubx_evk_iris_w1/ubx_evk_iris_w1_common.dtsi:41 */
			label = "IRIS RGB_BLUE";      /* in zephyr/boards/u-blox/ubx_evk_iris_w1/ubx_evk_iris_w1_common.dtsi:42 */
		};

		/* node '/rgb_leds/led_2' defined in zephyr/boards/u-blox/ubx_evk_iris_w1/ubx_evk_iris_w1_common.dtsi:45 */
		rgb_green: led_2 {
			gpios = < &hsgpio1 0xb 0x1 >; /* in zephyr/boards/u-blox/ubx_evk_iris_w1/ubx_evk_iris_w1_common.dtsi:46 */
			label = "IRIS RGB_GREEN";     /* in zephyr/boards/u-blox/ubx_evk_iris_w1/ubx_evk_iris_w1_common.dtsi:47 */
		};

		/* node '/rgb_leds/led_3' defined in zephyr/boards/u-blox/ubx_evk_iris_w1/ubx_evk_iris_w1_common.dtsi:50 */
		rgb_red: led_3 {
			gpios = < &hsgpio1 0xc 0x1 >; /* in zephyr/boards/u-blox/ubx_evk_iris_w1/ubx_evk_iris_w1_common.dtsi:51 */
			label = "IRIS RGB_RED";       /* in zephyr/boards/u-blox/ubx_evk_iris_w1/ubx_evk_iris_w1_common.dtsi:52 */
		};
	};

	/* node '/sw' defined in zephyr/boards/u-blox/ubx_evk_iris_w1/ubx_evk_iris_w1_common.dtsi:56 */
	sw {
		compatible = "gpio-keys"; /* in zephyr/boards/u-blox/ubx_evk_iris_w1/ubx_evk_iris_w1_common.dtsi:57 */

		/* node '/sw/sw_1' defined in zephyr/boards/u-blox/ubx_evk_iris_w1/ubx_evk_iris_w1_common.dtsi:59 */
		user_button_0: sw_1 {
			label = "IRIS SWITCH_1";      /* in zephyr/boards/u-blox/ubx_evk_iris_w1/ubx_evk_iris_w1_common.dtsi:60 */
			gpios = < &hsgpio1 0xd 0x1 >; /* in zephyr/boards/u-blox/ubx_evk_iris_w1/ubx_evk_iris_w1_common.dtsi:61 */
			zephyr,code = < 0x2 >;        /* in zephyr/boards/u-blox/ubx_evk_iris_w1/ubx_evk_iris_w1_common.dtsi:62 */
		};

		/* node '/sw/sw_2' defined in zephyr/boards/u-blox/ubx_evk_iris_w1/ubx_evk_iris_w1_common.dtsi:65 */
		user_button_1: sw_2 {
			label = "IRIS SWITCH_2";       /* in zephyr/boards/u-blox/ubx_evk_iris_w1/ubx_evk_iris_w1_common.dtsi:66 */
			gpios = < &hsgpio1 0x13 0x1 >; /* in zephyr/boards/u-blox/ubx_evk_iris_w1/ubx_evk_iris_w1_common.dtsi:67 */
			zephyr,code = < 0x3 >;         /* in zephyr/boards/u-blox/ubx_evk_iris_w1/ubx_evk_iris_w1_common.dtsi:68 */
		};
	};
};
